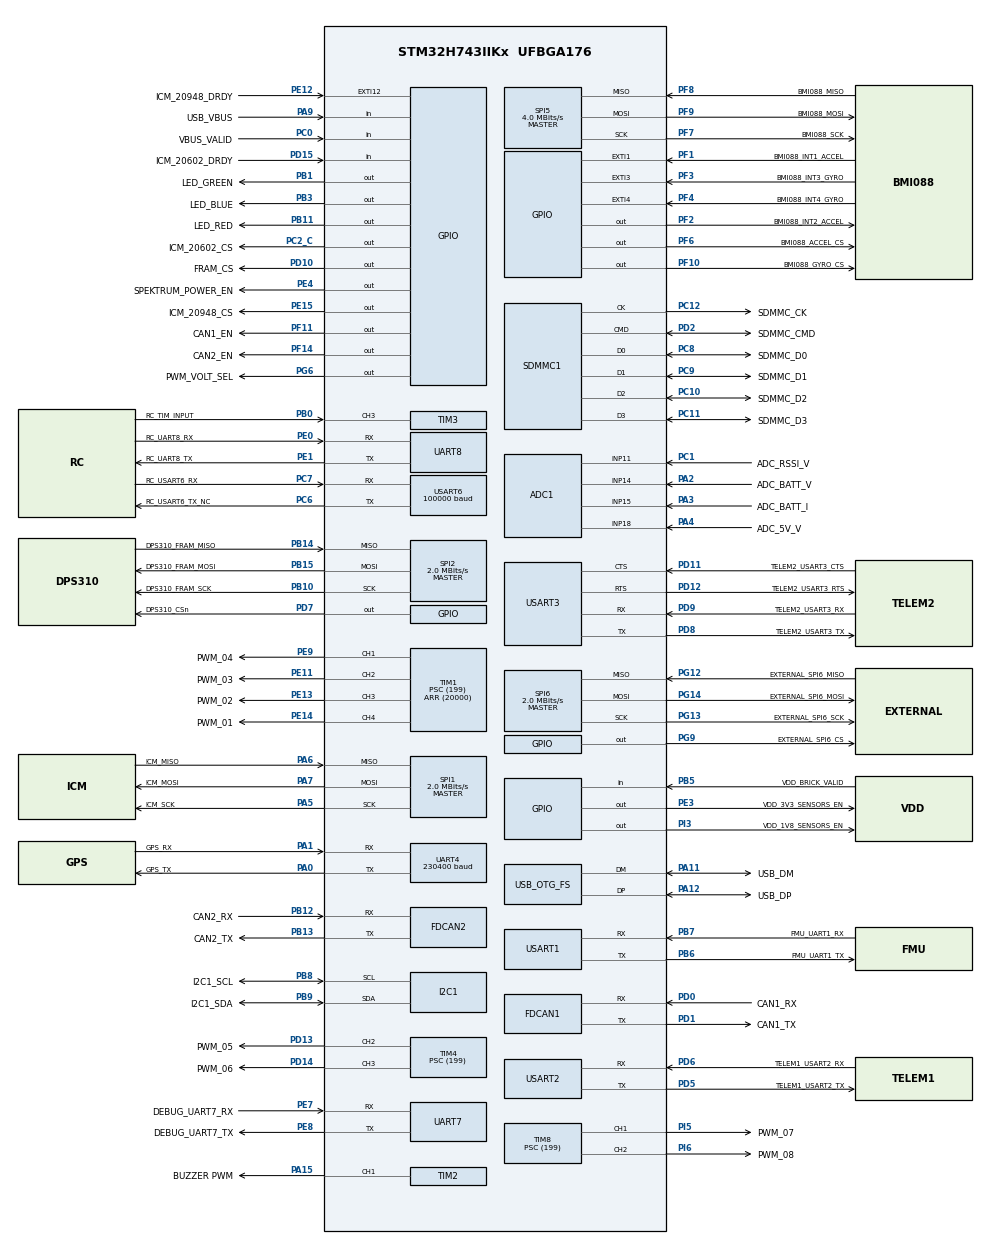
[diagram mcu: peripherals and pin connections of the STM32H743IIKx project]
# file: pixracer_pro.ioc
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ADC1.Channel-0\#ChannelRegularConversion=ADC_CHANNEL_11
ADC1.Channel-1\#ChannelRegularConversion=ADC_CHANNEL_14
ADC1.Channel-2\#ChannelRegularConversion=ADC_CHANNEL_15
ADC1.Channel-3\#ChannelRegularConversion=ADC_CHANNEL_18
ADC1.ClockPrescaler=ADC_CLOCK_ASYNC_DIV32
ADC1.ClockPrescalerADC3=ADC_CLOCK_ASYNC_DIV32
ADC1.ContinuousConvMode=DISABLE
ADC1.ConversionDataManagement=ADC_CONVERSIONDATA_DMA_ONESHOT
ADC1.EOCSelection=ADC_EOC_SEQ_CONV
ADC1.NbrOfConversion=4
ADC1.NbrOfConversionFlag=1
ADC1.OffsetNumber-0\#ChannelRegularConversion=ADC_OFFSET_NONE
ADC1.OffsetNumber-1\#ChannelRegularConversion=ADC_OFFSET_NONE
ADC1.OffsetNumber-2\#ChannelRegularConversion=ADC_OFFSET_NONE
ADC1.OffsetNumber-3\#ChannelRegularConversion=ADC_OFFSET_NONE
ADC1.OffsetSignedSaturation-0\#ChannelRegularConversion=DISABLE
ADC1.OffsetSignedSaturation-1\#ChannelRegularConversion=DISABLE
ADC1.OffsetSignedSaturation-2\#ChannelRegularConversion=DISABLE
ADC1.OffsetSignedSaturation-3\#ChannelRegularConversion=DISABLE
ADC1.Rank-0\#ChannelRegularConversion=1
ADC1.Rank-1\#ChannelRegularConversion=2
ADC1.Rank-2\#ChannelRegularConversion=3
ADC1.Rank-3\#ChannelRegularConversion=4
ADC1.SamplingTime-0\#ChannelRegularConversion=ADC_SAMPLETIME_810CYCLES_5
ADC1.SamplingTime-1\#ChannelRegularConversion=ADC_SAMPLETIME_810CYCLES_5
ADC1.SamplingTime-2\#ChannelRegularConversion=ADC_SAMPLETIME_810CYCLES_5
ADC1.SamplingTime-3\#ChannelRegularConversion=ADC_SAMPLETIME_810CYCLES_5
ADC1.master=1
ADC3.Channel-0\#ChannelRegularConversion=ADC_CHANNEL_TEMPSENSOR
ADC3.Channel-1\#ChannelRegularConversion=ADC_CHANNEL_VBAT
ADC3.Channel-2\#ChannelRegularConversion=ADC_CHANNEL_VREFINT
ADC3.ClockPrescalerADC3=ADC_CLOCK_ASYNC_DIV32
ADC3.ConversionDataManagement=ADC_CONVERSIONDATA_DMA_ONESHOT
ADC3.EOCSelection=ADC_EOC_SEQ_CONV
ADC3.NbrOfConversion=3
ADC3.NbrOfConversionFlag=1
ADC3.OffsetNumber-0\#ChannelRegularConversion=ADC_OFFSET_NONE
ADC3.OffsetNumber-1\#ChannelRegularConversion=ADC_OFFSET_NONE
ADC3.OffsetNumber-2\#ChannelRegularConversion=ADC_OFFSET_NONE
ADC3.OffsetSignedSaturation-0\#ChannelRegularConversion=DISABLE
ADC3.OffsetSignedSaturation-1\#ChannelRegularConversion=DISABLE
ADC3.OffsetSignedSaturation-2\#ChannelRegularConversion=DISABLE
ADC3.Rank-0\#ChannelRegularConversion=1
ADC3.Rank-1\#ChannelRegularConversion=2
ADC3.Rank-2\#ChannelRegularConversion=3
ADC3.SamplingTime-0\#ChannelRegularConversion=ADC_SAMPLETIME_810CYCLES_5
ADC3.SamplingTime-1\#ChannelRegularConversion=ADC_SAMPLETIME_810CYCLES_5
ADC3.SamplingTime-2\#ChannelRegularConversion=ADC_SAMPLETIME_810CYCLES_5
Bdma.ADC3.0.Direction=DMA_PERIPH_TO_MEMORY
Bdma.ADC3.0.EventEnable=DISABLE
Bdma.ADC3.0.Instance=BDMA_Channel0
Bdma.ADC3.0.MemDataAlignment=DMA_MDATAALIGN_WORD
Bdma.ADC3.0.MemInc=DMA_MINC_ENABLE
Bdma.ADC3.0.Mode=DMA_NORMAL
Bdma.ADC3.0.PeriphDataAlignment=DMA_PDATAALIGN_WORD
Bdma.ADC3.0.PeriphInc=DMA_PINC_DISABLE
Bdma.ADC3.0.Polarity=HAL_DMAMUX_REQ_GEN_RISING
Bdma.ADC3.0.Priority=DMA_PRIORITY_LOW
Bdma.ADC3.0.RequestNumber=1
Bdma.ADC3.0.SignalID=NONE
Bdma.ADC3.0.SyncEnable=DISABLE
Bdma.ADC3.0.SyncPolarity=HAL_DMAMUX_SYNC_NO_EVENT
Bdma.ADC3.0.SyncRequestNumber=1
Bdma.ADC3.0.SyncSignalID=NONE
Bdma.Request0=ADC3
Bdma.Request1=SPI6_RX
Bdma.Request2=SPI6_TX
Bdma.RequestsNb=3
Bdma.SPI6_RX.1.Direction=DMA_PERIPH_TO_MEMORY
Bdma.SPI6_RX.1.EventEnable=DISABLE
Bdma.SPI6_RX.1.Instance=BDMA_Channel1
Bdma.SPI6_RX.1.MemDataAlignment=DMA_MDATAALIGN_BYTE
Bdma.SPI6_RX.1.MemInc=DMA_MINC_ENABLE
Bdma.SPI6_RX.1.Mode=DMA_NORMAL
Bdma.SPI6_RX.1.PeriphDataAlignment=DMA_PDATAALIGN_BYTE
Bdma.SPI6_RX.1.PeriphInc=DMA_PINC_DISABLE
Bdma.SPI6_RX.1.Polarity=HAL_DMAMUX_REQ_GEN_RISING
Bdma.SPI6_RX.1.Priority=DMA_PRIORITY_LOW
Bdma.SPI6_RX.1.RequestNumber=1
Bdma.SPI6_RX.1.SignalID=NONE
Bdma.SPI6_RX.1.SyncEnable=DISABLE
Bdma.SPI6_RX.1.SyncPolarity=HAL_DMAMUX_SYNC_NO_EVENT
Bdma.SPI6_RX.1.SyncRequestNumber=1
Bdma.SPI6_RX.1.SyncSignalID=NONE
Bdma.SPI6_TX.2.Direction=DMA_MEMORY_TO_PERIPH
Bdma.SPI6_TX.2.EventEnable=DISABLE
Bdma.SPI6_TX.2.Instance=BDMA_Channel2
Bdma.SPI6_TX.2.MemDataAlignment=DMA_MDATAALIGN_BYTE
Bdma.SPI6_TX.2.MemInc=DMA_MINC_ENABLE
Bdma.SPI6_TX.2.Mode=DMA_NORMAL
Bdma.SPI6_TX.2.PeriphDataAlignment=DMA_PDATAALIGN_BYTE
Bdma.SPI6_TX.2.PeriphInc=DMA_PINC_DISABLE
Bdma.SPI6_TX.2.Polarity=HAL_DMAMUX_REQ_GEN_RISING
Bdma.SPI6_TX.2.Priority=DMA_PRIORITY_LOW
Bdma.SPI6_TX.2.RequestNumber=1
Bdma.SPI6_TX.2.SignalID=NONE
Bdma.SPI6_TX.2.SyncEnable=DISABLE
Bdma.SPI6_TX.2.SyncPolarity=HAL_DMAMUX_SYNC_NO_EVENT
Bdma.SPI6_TX.2.SyncRequestNumber=1
Bdma.SPI6_TX.2.SyncSignalID=NONE
CORTEX_M7.AccessPermission-Cortex_Memory_Protection_Unit_Region0_Settings=MPU_REGION_FULL_ACCESS
CORTEX_M7.AccessPermission-Cortex_Memory_Protection_Unit_Region1_Settings=MPU_REGION_FULL_ACCESS
CORTEX_M7.BaseAddress-Cortex_Memory_Protection_Unit_Region0_Settings=0x30040000
CORTEX_M7.BaseAddress-Cortex_Memory_Protection_Unit_Region1_Settings=0x38000000
CORTEX_M7.CPU_DCache=Enabled
CORTEX_M7.CPU_ICache=Enabled
CORTEX_M7.Enable-Cortex_Memory_Protection_Unit_Region0_Settings=MPU_REGION_ENABLE
CORTEX_M7.Enable-Cortex_Memory_Protection_Unit_Region1_Settings=MPU_REGION_ENABLE
CORTEX_M7.IsCacheable-Cortex_Memory_Protection_Unit_Region0_Settings=MPU_ACCESS_CACHEABLE
CORTEX_M7.IsCacheable-Cortex_Memory_Protection_Unit_Region1_Settings=MPU_ACCESS_CACHEABLE
CORTEX_M7.IsShareable-Cortex_Memory_Protection_Unit_Region0_Settings=MPU_ACCESS_SHAREABLE
CORTEX_M7.IsShareable-Cortex_Memory_Protection_Unit_Region1_Settings=MPU_ACCESS_SHAREABLE
CORTEX_M7.MPU_Control=MPU_PRIVILEGED_DEFAULT
CORTEX_M7.Size-Cortex_Memory_Protection_Unit_Region0_Settings=MPU_REGION_SIZE_32KB
CORTEX_M7.Size-Cortex_Memory_Protection_Unit_Region1_Settings=MPU_REGION_SIZE_64KB
Dma.ADC1.0.Direction=DMA_PERIPH_TO_MEMORY
Dma.ADC1.0.EventEnable=DISABLE
Dma.ADC1.0.FIFOMode=DMA_FIFOMODE_ENABLE
Dma.ADC1.0.FIFOThreshold=DMA_FIFO_THRESHOLD_FULL
Dma.ADC1.0.Instance=DMA1_Stream0
Dma.ADC1.0.MemBurst=DMA_MBURST_SINGLE
Dma.ADC1.0.MemDataAlignment=DMA_MDATAALIGN_WORD
Dma.ADC1.0.MemInc=DMA_MINC_ENABLE
Dma.ADC1.0.Mode=DMA_NORMAL
Dma.ADC1.0.PeriphBurst=DMA_PBURST_SINGLE
Dma.ADC1.0.PeriphDataAlignment=DMA_PDATAALIGN_WORD
Dma.ADC1.0.PeriphInc=DMA_PINC_DISABLE
Dma.ADC1.0.Polarity=HAL_DMAMUX_REQ_GEN_RISING
Dma.ADC1.0.Priority=DMA_PRIORITY_LOW
Dma.ADC1.0.RequestNumber=1
Dma.ADC1.0.SignalID=NONE
Dma.ADC1.0.SyncEnable=DISABLE
Dma.ADC1.0.SyncPolarity=HAL_DMAMUX_SYNC_NO_EVENT
Dma.ADC1.0.SyncRequestNumber=1
Dma.ADC1.0.SyncSignalID=NONE
Dma.I2C1_RX.9.Direction=DMA_PERIPH_TO_MEMORY
Dma.I2C1_RX.9.EventEnable=DISABLE
Dma.I2C1_RX.9.FIFOMode=DMA_FIFOMODE_ENABLE
Dma.I2C1_RX.9.FIFOThreshold=DMA_FIFO_THRESHOLD_FULL
Dma.I2C1_RX.9.Instance=DMA2_Stream2
Dma.I2C1_RX.9.MemBurst=DMA_MBURST_SINGLE
Dma.I2C1_RX.9.MemDataAlignment=DMA_MDATAALIGN_BYTE
Dma.I2C1_RX.9.MemInc=DMA_MINC_ENABLE
Dma.I2C1_RX.9.Mode=DMA_NORMAL
Dma.I2C1_RX.9.PeriphBurst=DMA_PBURST_SINGLE
Dma.I2C1_RX.9.PeriphDataAlignment=DMA_PDATAALIGN_BYTE
Dma.I2C1_RX.9.PeriphInc=DMA_PINC_DISABLE
Dma.I2C1_RX.9.Polarity=HAL_DMAMUX_REQ_GEN_RISING
Dma.I2C1_RX.9.Priority=DMA_PRIORITY_LOW
Dma.I2C1_RX.9.RequestNumber=1
Dma.I2C1_RX.9.SignalID=NONE
Dma.I2C1_RX.9.SyncEnable=DISABLE
Dma.I2C1_RX.9.SyncPolarity=HAL_DMAMUX_SYNC_NO_EVENT
Dma.I2C1_RX.9.SyncRequestNumber=1
Dma.I2C1_RX.9.SyncSignalID=NONE
Dma.I2C1_TX.10.Direction=DMA_MEMORY_TO_PERIPH
Dma.I2C1_TX.10.EventEnable=DISABLE
Dma.I2C1_TX.10.FIFOMode=DMA_FIFOMODE_ENABLE
Dma.I2C1_TX.10.FIFOThreshold=DMA_FIFO_THRESHOLD_FULL
Dma.I2C1_TX.10.Instance=DMA2_Stream3
Dma.I2C1_TX.10.MemBurst=DMA_MBURST_SINGLE
Dma.I2C1_TX.10.MemDataAlignment=DMA_MDATAALIGN_BYTE
Dma.I2C1_TX.10.MemInc=DMA_MINC_ENABLE
Dma.I2C1_TX.10.Mode=DMA_NORMAL
Dma.I2C1_TX.10.PeriphBurst=DMA_PBURST_SINGLE
Dma.I2C1_TX.10.PeriphDataAlignment=DMA_PDATAALIGN_BYTE
Dma.I2C1_TX.10.PeriphInc=DMA_PINC_DISABLE
Dma.I2C1_TX.10.Polarity=HAL_DMAMUX_REQ_GEN_RISING
Dma.I2C1_TX.10.Priority=DMA_PRIORITY_LOW
Dma.I2C1_TX.10.RequestNumber=1
Dma.I2C1_TX.10.SignalID=NONE
Dma.I2C1_TX.10.SyncEnable=DISABLE
Dma.I2C1_TX.10.SyncPolarity=HAL_DMAMUX_SYNC_NO_EVENT
Dma.I2C1_TX.10.SyncRequestNumber=1
Dma.I2C1_TX.10.SyncSignalID=NONE
Dma.Request0=ADC1
Dma.Request1=SPI1_RX
Dma.Request10=I2C1_TX
Dma.Request11=TIM1_UP
Dma.Request12=USART2_TX
Dma.Request13=TIM8_UP
Dma.Request14=TIM4_UP
Dma.Request2=SPI1_TX
Dma.Request3=SPI2_RX
Dma.Request4=SPI2_TX
Dma.Request5=SPI5_RX
Dma.Request6=SPI5_TX
Dma.Request7=UART4_RX
Dma.Request8=USART6_RX
Dma.Request9=I2C1_RX
Dma.SPI1_RX.1.Direction=DMA_PERIPH_TO_MEMORY
Dma.SPI1_RX.1.EventEnable=DISABLE
Dma.SPI1_RX.1.FIFOMode=DMA_FIFOMODE_ENABLE
Dma.SPI1_RX.1.FIFOThreshold=DMA_FIFO_THRESHOLD_FULL
Dma.SPI1_RX.1.Instance=DMA1_Stream1
Dma.SPI1_RX.1.MemBurst=DMA_MBURST_SINGLE
Dma.SPI1_RX.1.MemDataAlignment=DMA_MDATAALIGN_BYTE
Dma.SPI1_RX.1.MemInc=DMA_MINC_ENABLE
Dma.SPI1_RX.1.Mode=DMA_NORMAL
Dma.SPI1_RX.1.PeriphBurst=DMA_PBURST_SINGLE
Dma.SPI1_RX.1.PeriphDataAlignment=DMA_PDATAALIGN_BYTE
Dma.SPI1_RX.1.PeriphInc=DMA_PINC_DISABLE
Dma.SPI1_RX.1.Polarity=HAL_DMAMUX_REQ_GEN_RISING
Dma.SPI1_RX.1.Priority=DMA_PRIORITY_LOW
Dma.SPI1_RX.1.RequestNumber=1
Dma.SPI1_RX.1.SignalID=NONE
Dma.SPI1_RX.1.SyncEnable=DISABLE
Dma.SPI1_RX.1.SyncPolarity=HAL_DMAMUX_SYNC_NO_EVENT
Dma.SPI1_RX.1.SyncRequestNumber=1
Dma.SPI1_RX.1.SyncSignalID=NONE
Dma.SPI1_TX.2.Direction=DMA_MEMORY_TO_PERIPH
Dma.SPI1_TX.2.EventEnable=DISABLE
Dma.SPI1_TX.2.FIFOMode=DMA_FIFOMODE_DISABLE
Dma.SPI1_TX.2.Instance=DMA1_Stream2
Dma.SPI1_TX.2.MemDataAlignment=DMA_MDATAALIGN_BYTE
Dma.SPI1_TX.2.MemInc=DMA_MINC_ENABLE
Dma.SPI1_TX.2.Mode=DMA_NORMAL
Dma.SPI1_TX.2.PeriphDataAlignment=DMA_PDATAALIGN_BYTE
Dma.SPI1_TX.2.PeriphInc=DMA_PINC_DISABLE
Dma.SPI1_TX.2.Polarity=HAL_DMAMUX_REQ_GEN_RISING
Dma.SPI1_TX.2.Priority=DMA_PRIORITY_LOW
Dma.SPI1_TX.2.RequestNumber=1
Dma.SPI1_TX.2.SignalID=NONE
Dma.SPI1_TX.2.SyncEnable=DISABLE
Dma.SPI1_TX.2.SyncPolarity=HAL_DMAMUX_SYNC_NO_EVENT
Dma.SPI1_TX.2.SyncRequestNumber=1
Dma.SPI1_TX.2.SyncSignalID=NONE
Dma.SPI2_RX.3.Direction=DMA_PERIPH_TO_MEMORY
Dma.SPI2_RX.3.EventEnable=DISABLE
Dma.SPI2_RX.3.FIFOMode=DMA_FIFOMODE_ENABLE
Dma.SPI2_RX.3.FIFOThreshold=DMA_FIFO_THRESHOLD_FULL
Dma.SPI2_RX.3.Instance=DMA1_Stream3
Dma.SPI2_RX.3.MemBurst=DMA_MBURST_SINGLE
Dma.SPI2_RX.3.MemDataAlignment=DMA_MDATAALIGN_BYTE
Dma.SPI2_RX.3.MemInc=DMA_MINC_ENABLE
Dma.SPI2_RX.3.Mode=DMA_NORMAL
Dma.SPI2_RX.3.PeriphBurst=DMA_PBURST_SINGLE
Dma.SPI2_RX.3.PeriphDataAlignment=DMA_PDATAALIGN_BYTE
Dma.SPI2_RX.3.PeriphInc=DMA_PINC_DISABLE
Dma.SPI2_RX.3.Polarity=HAL_DMAMUX_REQ_GEN_RISING
Dma.SPI2_RX.3.Priority=DMA_PRIORITY_LOW
Dma.SPI2_RX.3.RequestNumber=1
Dma.SPI2_RX.3.SignalID=NONE
Dma.SPI2_RX.3.SyncEnable=DISABLE
Dma.SPI2_RX.3.SyncPolarity=HAL_DMAMUX_SYNC_NO_EVENT
Dma.SPI2_RX.3.SyncRequestNumber=1
Dma.SPI2_RX.3.SyncSignalID=NONE
Dma.SPI2_TX.4.Direction=DMA_MEMORY_TO_PERIPH
Dma.SPI2_TX.4.EventEnable=DISABLE
Dma.SPI2_TX.4.FIFOMode=DMA_FIFOMODE_ENABLE
Dma.SPI2_TX.4.FIFOThreshold=DMA_FIFO_THRESHOLD_FULL
Dma.SPI2_TX.4.Instance=DMA1_Stream4
Dma.SPI2_TX.4.MemBurst=DMA_MBURST_SINGLE
Dma.SPI2_TX.4.MemDataAlignment=DMA_MDATAALIGN_BYTE
Dma.SPI2_TX.4.MemInc=DMA_MINC_ENABLE
Dma.SPI2_TX.4.Mode=DMA_NORMAL
Dma.SPI2_TX.4.PeriphBurst=DMA_PBURST_SINGLE
Dma.SPI2_TX.4.PeriphDataAlignment=DMA_PDATAALIGN_BYTE
Dma.SPI2_TX.4.PeriphInc=DMA_PINC_DISABLE
Dma.SPI2_TX.4.Polarity=HAL_DMAMUX_REQ_GEN_RISING
Dma.SPI2_TX.4.Priority=DMA_PRIORITY_LOW
Dma.SPI2_TX.4.RequestNumber=1
Dma.SPI2_TX.4.SignalID=NONE
Dma.SPI2_TX.4.SyncEnable=DISABLE
Dma.SPI2_TX.4.SyncPolarity=HAL_DMAMUX_SYNC_NO_EVENT
Dma.SPI2_TX.4.SyncRequestNumber=1
Dma.SPI2_TX.4.SyncSignalID=NONE
Dma.SPI5_RX.5.Direction=DMA_PERIPH_TO_MEMORY
Dma.SPI5_RX.5.EventEnable=DISABLE
Dma.SPI5_RX.5.FIFOMode=DMA_FIFOMODE_ENABLE
Dma.SPI5_RX.5.FIFOThreshold=DMA_FIFO_THRESHOLD_FULL
Dma.SPI5_RX.5.Instance=DMA1_Stream5
Dma.SPI5_RX.5.MemBurst=DMA_MBURST_SINGLE
Dma.SPI5_RX.5.MemDataAlignment=DMA_MDATAALIGN_BYTE
Dma.SPI5_RX.5.MemInc=DMA_MINC_ENABLE
Dma.SPI5_RX.5.Mode=DMA_NORMAL
Dma.SPI5_RX.5.PeriphBurst=DMA_PBURST_SINGLE
Dma.SPI5_RX.5.PeriphDataAlignment=DMA_PDATAALIGN_BYTE
Dma.SPI5_RX.5.PeriphInc=DMA_PINC_DISABLE
Dma.SPI5_RX.5.Polarity=HAL_DMAMUX_REQ_GEN_RISING
Dma.SPI5_RX.5.Priority=DMA_PRIORITY_LOW
Dma.SPI5_RX.5.RequestNumber=1
Dma.SPI5_RX.5.SignalID=NONE
Dma.SPI5_RX.5.SyncEnable=DISABLE
Dma.SPI5_RX.5.SyncPolarity=HAL_DMAMUX_SYNC_NO_EVENT
Dma.SPI5_RX.5.SyncRequestNumber=1
Dma.SPI5_RX.5.SyncSignalID=NONE
Dma.SPI5_TX.6.Direction=DMA_MEMORY_TO_PERIPH
Dma.SPI5_TX.6.EventEnable=DISABLE
Dma.SPI5_TX.6.FIFOMode=DMA_FIFOMODE_ENABLE
Dma.SPI5_TX.6.FIFOThreshold=DMA_FIFO_THRESHOLD_FULL
Dma.SPI5_TX.6.Instance=DMA1_Stream6
Dma.SPI5_TX.6.MemBurst=DMA_MBURST_SINGLE
Dma.SPI5_TX.6.MemDataAlignment=DMA_MDATAALIGN_BYTE
Dma.SPI5_TX.6.MemInc=DMA_MINC_ENABLE
Dma.SPI5_TX.6.Mode=DMA_NORMAL
Dma.SPI5_TX.6.PeriphBurst=DMA_PBURST_SINGLE
Dma.SPI5_TX.6.PeriphDataAlignment=DMA_PDATAALIGN_BYTE
Dma.SPI5_TX.6.PeriphInc=DMA_PINC_DISABLE
Dma.SPI5_TX.6.Polarity=HAL_DMAMUX_REQ_GEN_RISING
Dma.SPI5_TX.6.Priority=DMA_PRIORITY_LOW
Dma.SPI5_TX.6.RequestNumber=1
Dma.SPI5_TX.6.SignalID=NONE
Dma.SPI5_TX.6.SyncEnable=DISABLE
Dma.SPI5_TX.6.SyncPolarity=HAL_DMAMUX_SYNC_NO_EVENT
Dma.SPI5_TX.6.SyncRequestNumber=1
Dma.SPI5_TX.6.SyncSignalID=NONE
Dma.TIM1_UP.11.Direction=DMA_MEMORY_TO_PERIPH
Dma.TIM1_UP.11.EventEnable=DISABLE
Dma.TIM1_UP.11.FIFOMode=DMA_FIFOMODE_ENABLE
Dma.TIM1_UP.11.FIFOThreshold=DMA_FIFO_THRESHOLD_FULL
Dma.TIM1_UP.11.Instance=DMA2_Stream6
Dma.TIM1_UP.11.MemBurst=DMA_MBURST_SINGLE
Dma.TIM1_UP.11.MemDataAlignment=DMA_MDATAALIGN_WORD
Dma.TIM1_UP.11.MemInc=DMA_MINC_ENABLE
Dma.TIM1_UP.11.Mode=DMA_NORMAL
Dma.TIM1_UP.11.PeriphBurst=DMA_PBURST_SINGLE
Dma.TIM1_UP.11.PeriphDataAlignment=DMA_PDATAALIGN_WORD
Dma.TIM1_UP.11.PeriphInc=DMA_PINC_DISABLE
Dma.TIM1_UP.11.Polarity=HAL_DMAMUX_REQ_GEN_RISING
Dma.TIM1_UP.11.Priority=DMA_PRIORITY_LOW
Dma.TIM1_UP.11.RequestNumber=1
Dma.TIM1_UP.11.SignalID=NONE
Dma.TIM1_UP.11.SyncEnable=DISABLE
Dma.TIM1_UP.11.SyncPolarity=HAL_DMAMUX_SYNC_NO_EVENT
Dma.TIM1_UP.11.SyncRequestNumber=1
Dma.TIM1_UP.11.SyncSignalID=NONE
Dma.TIM4_UP.14.Direction=DMA_MEMORY_TO_PERIPH
Dma.TIM4_UP.14.EventEnable=DISABLE
Dma.TIM4_UP.14.FIFOMode=DMA_FIFOMODE_ENABLE
Dma.TIM4_UP.14.FIFOThreshold=DMA_FIFO_THRESHOLD_FULL
Dma.TIM4_UP.14.Instance=DMA2_Stream4
Dma.TIM4_UP.14.MemBurst=DMA_MBURST_SINGLE
Dma.TIM4_UP.14.MemDataAlignment=DMA_MDATAALIGN_WORD
Dma.TIM4_UP.14.MemInc=DMA_MINC_ENABLE
Dma.TIM4_UP.14.Mode=DMA_NORMAL
Dma.TIM4_UP.14.PeriphBurst=DMA_PBURST_SINGLE
Dma.TIM4_UP.14.PeriphDataAlignment=DMA_PDATAALIGN_WORD
Dma.TIM4_UP.14.PeriphInc=DMA_PINC_DISABLE
Dma.TIM4_UP.14.Polarity=HAL_DMAMUX_REQ_GEN_RISING
Dma.TIM4_UP.14.Priority=DMA_PRIORITY_LOW
Dma.TIM4_UP.14.RequestNumber=1
Dma.TIM4_UP.14.SignalID=NONE
Dma.TIM4_UP.14.SyncEnable=DISABLE
Dma.TIM4_UP.14.SyncPolarity=HAL_DMAMUX_SYNC_NO_EVENT
Dma.TIM4_UP.14.SyncRequestNumber=1
Dma.TIM4_UP.14.SyncSignalID=NONE
Dma.TIM8_UP.13.Direction=DMA_MEMORY_TO_PERIPH
Dma.TIM8_UP.13.EventEnable=DISABLE
Dma.TIM8_UP.13.FIFOMode=DMA_FIFOMODE_ENABLE
Dma.TIM8_UP.13.FIFOThreshold=DMA_FIFO_THRESHOLD_FULL
Dma.TIM8_UP.13.Instance=DMA2_Stream5
Dma.TIM8_UP.13.MemBurst=DMA_MBURST_SINGLE
Dma.TIM8_UP.13.MemDataAlignment=DMA_MDATAALIGN_WORD
Dma.TIM8_UP.13.MemInc=DMA_MINC_ENABLE
Dma.TIM8_UP.13.Mode=DMA_NORMAL
Dma.TIM8_UP.13.PeriphBurst=DMA_PBURST_SINGLE
Dma.TIM8_UP.13.PeriphDataAlignment=DMA_PDATAALIGN_WORD
Dma.TIM8_UP.13.PeriphInc=DMA_PINC_DISABLE
Dma.TIM8_UP.13.Polarity=HAL_DMAMUX_REQ_GEN_RISING
Dma.TIM8_UP.13.Priority=DMA_PRIORITY_LOW
Dma.TIM8_UP.13.RequestNumber=1
Dma.TIM8_UP.13.SignalID=NONE
Dma.TIM8_UP.13.SyncEnable=DISABLE
Dma.TIM8_UP.13.SyncPolarity=HAL_DMAMUX_SYNC_NO_EVENT
Dma.TIM8_UP.13.SyncRequestNumber=1
Dma.TIM8_UP.13.SyncSignalID=NONE
Dma.UART4_RX.7.Direction=DMA_PERIPH_TO_MEMORY
Dma.UART4_RX.7.EventEnable=DISABLE
Dma.UART4_RX.7.FIFOMode=DMA_FIFOMODE_ENABLE
Dma.UART4_RX.7.FIFOThreshold=DMA_FIFO_THRESHOLD_FULL
Dma.UART4_RX.7.Instance=DMA1_Stream7
Dma.UART4_RX.7.MemBurst=DMA_MBURST_SINGLE
Dma.UART4_RX.7.MemDataAlignment=DMA_MDATAALIGN_BYTE
Dma.UART4_RX.7.MemInc=DMA_MINC_ENABLE
Dma.UART4_RX.7.Mode=DMA_NORMAL
Dma.UART4_RX.7.PeriphBurst=DMA_PBURST_SINGLE
Dma.UART4_RX.7.PeriphDataAlignment=DMA_PDATAALIGN_BYTE
Dma.UART4_RX.7.PeriphInc=DMA_PINC_DISABLE
Dma.UART4_RX.7.Polarity=HAL_DMAMUX_REQ_GEN_RISING
Dma.UART4_RX.7.Priority=DMA_PRIORITY_LOW
Dma.UART4_RX.7.RequestNumber=1
Dma.UART4_RX.7.SignalID=NONE
Dma.UART4_RX.7.SyncEnable=DISABLE
Dma.UART4_RX.7.SyncPolarity=HAL_DMAMUX_SYNC_NO_EVENT
Dma.UART4_RX.7.SyncRequestNumber=1
Dma.UART4_RX.7.SyncSignalID=NONE
Dma.USART2_TX.12.Direction=DMA_MEMORY_TO_PERIPH
Dma.USART2_TX.12.EventEnable=DISABLE
Dma.USART2_TX.12.FIFOMode=DMA_FIFOMODE_ENABLE
Dma.USART2_TX.12.FIFOThreshold=DMA_FIFO_THRESHOLD_FULL
Dma.USART2_TX.12.Instance=DMA2_Stream0
Dma.USART2_TX.12.MemBurst=DMA_MBURST_SINGLE
Dma.USART2_TX.12.MemDataAlignment=DMA_MDATAALIGN_BYTE
Dma.USART2_TX.12.MemInc=DMA_MINC_ENABLE
Dma.USART2_TX.12.Mode=DMA_NORMAL
Dma.USART2_TX.12.PeriphBurst=DMA_PBURST_SINGLE
Dma.USART2_TX.12.PeriphDataAlignment=DMA_PDATAALIGN_BYTE
Dma.USART2_TX.12.PeriphInc=DMA_PINC_DISABLE
Dma.USART2_TX.12.Polarity=HAL_DMAMUX_REQ_GEN_RISING
Dma.USART2_TX.12.Priority=DMA_PRIORITY_LOW
Dma.USART2_TX.12.RequestNumber=1
Dma.USART2_TX.12.SignalID=NONE
Dma.USART2_TX.12.SyncEnable=DISABLE
Dma.USART2_TX.12.SyncPolarity=HAL_DMAMUX_SYNC_NO_EVENT
Dma.USART2_TX.12.SyncRequestNumber=1
Dma.USART2_TX.12.SyncSignalID=NONE
Dma.USART6_RX.8.Direction=DMA_PERIPH_TO_MEMORY
Dma.USART6_RX.8.EventEnable=DISABLE
Dma.USART6_RX.8.FIFOMode=DMA_FIFOMODE_ENABLE
Dma.USART6_RX.8.FIFOThreshold=DMA_FIFO_THRESHOLD_FULL
Dma.USART6_RX.8.Instance=DMA2_Stream1
Dma.USART6_RX.8.MemBurst=DMA_MBURST_SINGLE
Dma.USART6_RX.8.MemDataAlignment=DMA_MDATAALIGN_BYTE
Dma.USART6_RX.8.MemInc=DMA_MINC_ENABLE
Dma.USART6_RX.8.Mode=DMA_NORMAL
Dma.USART6_RX.8.PeriphBurst=DMA_PBURST_SINGLE
Dma.USART6_RX.8.PeriphDataAlignment=DMA_PDATAALIGN_BYTE
Dma.USART6_RX.8.PeriphInc=DMA_PINC_DISABLE
Dma.USART6_RX.8.Polarity=HAL_DMAMUX_REQ_GEN_RISING
Dma.USART6_RX.8.Priority=DMA_PRIORITY_LOW
Dma.USART6_RX.8.RequestNumber=1
Dma.USART6_RX.8.SignalID=NONE
Dma.USART6_RX.8.SyncEnable=DISABLE
Dma.USART6_RX.8.SyncPolarity=HAL_DMAMUX_SYNC_NO_EVENT
Dma.USART6_RX.8.SyncRequestNumber=1
Dma.USART6_RX.8.SyncSignalID=NONE
FDCAN1.CalculateBaudRateNominal=200000
FDCAN1.CalculateTimeBitNominal=5000
FDCAN1.CalculateTimeQuantumNominal=1000.0
FDCAN2.CalculateBaudRateNominal=200000
FDCAN2.CalculateTimeBitNominal=5000
FDCAN2.CalculateTimeQuantumNominal=1000.0
I2C1.Timing=0x10C0ECFF
Mcu.Family=STM32H7
Mcu.Name=STM32H743IIKx
Mcu.Package=UFBGA176
NVIC.ADC3_IRQn=true\:5\:0\:true\:false\:true\:true\:true\:true
NVIC.ADC_IRQn=true\:5\:0\:true\:false\:true\:true\:true\:true
NVIC.BDMA_Channel0_IRQn=true\:5\:0\:true\:false\:true\:false\:true\:true
NVIC.BDMA_Channel1_IRQn=true\:5\:0\:true\:false\:true\:false\:true\:true
NVIC.BDMA_Channel2_IRQn=true\:5\:0\:true\:false\:true\:false\:true\:true
NVIC.DMA1_Stream0_IRQn=true\:5\:0\:true\:false\:true\:false\:true\:true
NVIC.DMA1_Stream1_IRQn=true\:5\:0\:true\:false\:true\:false\:true\:true
NVIC.DMA1_Stream2_IRQn=true\:5\:0\:true\:false\:true\:false\:true\:true
NVIC.DMA1_Stream3_IRQn=true\:5\:0\:true\:false\:true\:false\:true\:true
NVIC.DMA1_Stream4_IRQn=true\:5\:0\:true\:false\:true\:false\:true\:true
NVIC.DMA1_Stream5_IRQn=true\:5\:0\:true\:false\:true\:false\:true\:true
NVIC.DMA1_Stream6_IRQn=true\:5\:0\:true\:false\:true\:false\:true\:true
NVIC.DMA1_Stream7_IRQn=true\:5\:0\:true\:false\:true\:false\:true\:true
NVIC.DMA2_Stream0_IRQn=true\:1\:0\:true\:false\:true\:false\:true\:true
NVIC.DMA2_Stream1_IRQn=true\:5\:0\:true\:false\:true\:false\:true\:true
NVIC.DMA2_Stream2_IRQn=true\:5\:0\:true\:false\:true\:false\:true\:true
NVIC.DMA2_Stream3_IRQn=true\:5\:0\:true\:false\:true\:false\:true\:true
NVIC.DMA2_Stream4_IRQn=true\:0\:0\:false\:false\:true\:false\:true\:true
NVIC.DMA2_Stream5_IRQn=true\:5\:0\:true\:false\:true\:false\:true\:true
NVIC.DMA2_Stream6_IRQn=true\:5\:0\:true\:false\:true\:false\:true\:true
NVIC.EXTI15_10_IRQn=true\:5\:0\:true\:false\:true\:true\:true\:true
NVIC.EXTI1_IRQn=true\:5\:0\:true\:false\:true\:true\:true\:true
NVIC.EXTI3_IRQn=true\:5\:0\:true\:false\:true\:true\:true\:true
NVIC.EXTI4_IRQn=true\:0\:0\:true\:false\:true\:true\:true\:true
NVIC.I2C1_EV_IRQn=true\:5\:0\:true\:false\:true\:true\:true\:true
NVIC.OTG_FS_IRQn=true\:0\:0\:false\:false\:true\:true\:true\:true
NVIC.PriorityGroup=NVIC_PRIORITYGROUP_4
NVIC.SDMMC1_IRQn=true\:1\:0\:true\:false\:true\:true\:true\:true
NVIC.SPI1_IRQn=true\:5\:0\:true\:false\:true\:false\:true\:true
NVIC.SPI2_IRQn=true\:5\:0\:true\:false\:true\:false\:true\:true
NVIC.SPI5_IRQn=true\:5\:0\:true\:false\:true\:true\:true\:true
NVIC.SPI6_IRQn=true\:5\:0\:true\:false\:true\:true\:true\:true
NVIC.TIM7_IRQn=true\:5\:0\:true\:false\:true\:true\:true\:true
NVIC.UART4_IRQn=true\:5\:0\:true\:false\:true\:true\:true\:true
NVIC.UART7_IRQn=true\:5\:0\:true\:false\:true\:true\:true\:true
NVIC.UART8_IRQn=true\:5\:0\:true\:false\:true\:true\:true\:true
NVIC.USART1_IRQn=true\:5\:0\:true\:false\:true\:true\:true\:true
NVIC.USART2_IRQn=true\:1\:0\:true\:false\:true\:true\:true\:true
NVIC.USART3_IRQn=true\:5\:0\:true\:false\:true\:true\:true\:true
NVIC.USART6_IRQn=true\:5\:0\:true\:false\:true\:true\:true\:true
PA0.GPIO_Label=GPS_TX
PA0.Mode=Asynchronous
PA0.PinAttribute=Free
PA0.Signal=UART4_TX
PA1.GPIO_Label=GPS_RX
PA1.GPIO_PuPd=GPIO_PULLUP
PA1.Mode=Asynchronous
PA1.PinAttribute=Free
PA1.Signal=UART4_RX
PA11.GPIO_Label=USB_DM
PA11.Mode=Device_Only
PA11.PinAttribute=Free
PA11.Signal=USB_OTG_FS_DM
PA12.GPIO_Label=USB_DP
PA12.Mode=Device_Only
PA12.PinAttribute=Free
PA12.Signal=USB_OTG_FS_DP
PA13\ (JTMS/SWDIO).GPIO_Label=DEBUG_SWDIO
PA13\ (JTMS/SWDIO).Mode=Serial_Wire
PA13\ (JTMS/SWDIO).PinAttribute=Free
PA13\ (JTMS/SWDIO).Signal=DEBUG_JTMS-SWDIO
PA14\ (JTCK/SWCLK).GPIO_Label=DEBUG_SWCLK
PA14\ (JTCK/SWCLK).Mode=Serial_Wire
PA14\ (JTCK/SWCLK).PinAttribute=Free
PA14\ (JTCK/SWCLK).Signal=DEBUG_JTCK-SWCLK
PA15\ (JTDI).GPIO_Label=BUZZER PWM
PA15\ (JTDI).Signal=S_TIM2_CH1_ETR
PA2.GPIO_Label=ADC_BATT_V
PA2.PinAttribute=Free
PA2.Signal=ADCx_INP14
PA3.GPIO_Label=ADC_BATT_I
PA3.PinAttribute=Free
PA3.Signal=ADCx_INP15
PA4.GPIO_Label=ADC_5V_V
PA4.PinAttribute=Free
PA4.Signal=ADCx_INP18
PA5.GPIO_Label=ICM_SCK
PA5.Mode=Full_Duplex_Master
PA5.PinAttribute=Free
PA5.Signal=SPI1_SCK
PA6.GPIO_Label=ICM_MISO
PA6.Mode=Full_Duplex_Master
PA6.PinAttribute=Free
PA6.Signal=SPI1_MISO
PA7.GPIO_Label=ICM_MOSI
PA7.Mode=Full_Duplex_Master
PA7.PinAttribute=Free
PA7.Signal=SPI1_MOSI
PA9.GPIO_Label=USB_VBUS
PA9.Signal=GPIO_Input
PB0.GPIO_Label=RC_TIM_INPUT
PB0.PinAttribute=Free
PB0.Signal=S_TIM3_CH3
PB1.GPIO_Label=LED_GREEN
PB1.PinAttribute=Free
PB1.Signal=GPIO_Output
PB10.GPIO_Label=DPS310_FRAM_SCK
PB10.Mode=Full_Duplex_Master
PB10.PinAttribute=Free
PB10.Signal=SPI2_SCK
PB11.GPIO_Label=LED_RED
PB11.PinAttribute=Free
PB11.Signal=GPIO_Output
PB12.GPIO_Label=CAN2_RX
PB12.Mode=FDCAN_Activate
PB12.PinAttribute=Free
PB12.Signal=FDCAN2_RX
PB13.GPIO_Label=CAN2_TX
PB13.Mode=FDCAN_Activate
PB13.PinAttribute=Free
PB13.Signal=FDCAN2_TX
PB14.GPIO_Label=DPS310_FRAM_MISO
PB14.Mode=Full_Duplex_Master
PB14.PinAttribute=Free
PB14.Signal=SPI2_MISO
PB15.GPIO_Label=DPS310_FRAM_MOSI
PB15.Mode=Full_Duplex_Master
PB15.PinAttribute=Free
PB15.Signal=SPI2_MOSI
PB3\ (JTDO/TRACESWO).GPIO_Label=LED_BLUE
PB3\ (JTDO/TRACESWO).PinAttribute=Free
PB3\ (JTDO/TRACESWO).Signal=GPIO_Output
PB5.GPIO_Label=VDD_BRICK_VALID
PB5.PinAttribute=Free
PB5.Signal=GPIO_Input
PB6.GPIO_Label=FMU_UART1_TX
PB6.Mode=Asynchronous
PB6.PinAttribute=Free
PB6.Signal=USART1_TX
PB7.GPIO_Label=FMU_UART1_RX
PB7.GPIO_PuPd=GPIO_PULLUP
PB7.Mode=Asynchronous
PB7.PinAttribute=Free
PB7.Signal=USART1_RX
PB8.GPIO_Label=I2C1_SCL
PB8.Mode=I2C
PB8.PinAttribute=Free
PB8.Signal=I2C1_SCL
PB9.GPIO_Label=I2C1_SDA
PB9.Mode=I2C
PB9.PinAttribute=Free
PB9.Signal=I2C1_SDA
PC0.GPIO_Label=VBUS_VALID
PC0.PinAttribute=Free
PC0.Signal=GPIO_Input
PC1.GPIO_Label=ADC_RSSI_V
PC1.PinAttribute=Free
PC1.Signal=ADCx_INP11
PC10.GPIO_Label=SDMMC_D2
PC10.GPIO_PuPd=GPIO_PULLUP
PC10.Mode=SD_4_bits_Wide_bus
PC10.PinAttribute=Free
PC10.Signal=SDMMC1_D2
PC11.GPIO_Label=SDMMC_D3
PC11.GPIO_PuPd=GPIO_PULLUP
PC11.Mode=SD_4_bits_Wide_bus
PC11.PinAttribute=Free
PC11.Signal=SDMMC1_D3
PC12.GPIO_Label=SDMMC_CK
PC12.GPIO_PuPd=GPIO_PULLUP
PC12.Mode=SD_4_bits_Wide_bus
PC12.Signal=SDMMC1_CK
PC2_C.GPIO_Label=ICM_20602_CS
PC2_C.GPIO_PuPd=GPIO_PULLUP
PC2_C.PinAttribute=Free
PC2_C.PinState=GPIO_PIN_SET
PC2_C.Signal=GPIO_Output
PC6.GPIO_Label=RC_USART6_TX_NC
PC6.Mode=Asynchronous
PC6.PinAttribute=Free
PC6.Signal=USART6_TX
PC7.GPIO_Label=RC_USART6_RX 
PC7.GPIO_PuPd=GPIO_PULLUP
PC7.Mode=Asynchronous
PC7.PinAttribute=Free
PC7.Signal=USART6_RX
PC8.GPIO_Label=SDMMC_D0
PC8.GPIO_PuPd=GPIO_PULLUP
PC8.Mode=SD_4_bits_Wide_bus
PC8.PinAttribute=Free
PC8.Signal=SDMMC1_D0
PC9.GPIO_Label=SDMMC_D1
PC9.GPIO_PuPd=GPIO_PULLUP
PC9.Mode=SD_4_bits_Wide_bus
PC9.PinAttribute=Free
PC9.Signal=SDMMC1_D1
PD0.GPIO_Label=CAN1_RX
PD0.Mode=FDCAN_Activate
PD0.PinAttribute=Free
PD0.Signal=FDCAN1_RX
PD1.GPIO_Label=CAN1_TX
PD1.Mode=FDCAN_Activate
PD1.PinAttribute=Free
PD1.Signal=FDCAN1_TX
PD10.GPIO_Label=FRAM_CS
PD10.GPIO_PuPd=GPIO_PULLUP
PD10.PinAttribute=Free
PD10.PinState=GPIO_PIN_SET
PD10.Signal=GPIO_Output
PD11.GPIO_Label=TELEM2_USART3_CTS
PD11.Mode=CTS_RTS
PD11.PinAttribute=Free
PD11.Signal=USART3_CTS
PD12.GPIO_Label=TELEM2_USART3_RTS 
PD12.Mode=CTS_RTS
PD12.PinAttribute=Free
PD12.Signal=USART3_RTS
PD13.GPIO_Label=PWM_05
PD13.PinAttribute=Free
PD13.Signal=S_TIM4_CH2
PD14.GPIO_Label=PWM_06
PD14.PinAttribute=Free
PD14.Signal=S_TIM4_CH3
PD15.GPIO_Label=ICM_20602_DRDY
PD15.PinAttribute=Free
PD15.Signal=GPIO_Input
PD2.GPIO_Label=SDMMC_CMD
PD2.GPIO_PuPd=GPIO_PULLUP
PD2.Mode=SD_4_bits_Wide_bus
PD2.PinAttribute=Free
PD2.Signal=SDMMC1_CMD
PD3.GPIO_Label=TELEM1_USART2_CTS 
PD3.PinAttribute=Free
PD3.Signal=USART2_CTS
PD4.GPIO_Label=TELEM1_USART2_RTS 
PD4.PinAttribute=Free
PD4.Signal=USART2_RTS
PD5.GPIO_Label=TELEM1_USART2_TX
PD5.Mode=Asynchronous
PD5.PinAttribute=Free
PD5.Signal=USART2_TX
PD6.GPIO_Label=TELEM1_USART2_RX
PD6.GPIO_PuPd=GPIO_PULLUP
PD6.Mode=Asynchronous
PD6.PinAttribute=Free
PD6.Signal=USART2_RX
PD7.GPIO_Label=DPS310_CSn
PD7.GPIO_PuPd=GPIO_PULLUP
PD7.PinAttribute=Free
PD7.PinState=GPIO_PIN_SET
PD7.Signal=GPIO_Output
PD8.GPIO_Label=TELEM2_USART3_TX 
PD8.GPIO_PuPd=GPIO_NOPULL
PD8.Mode=Asynchronous
PD8.PinAttribute=Free
PD8.Signal=USART3_TX
PD9.GPIO_Label=TELEM2_USART3_RX 
PD9.GPIO_PuPd=GPIO_PULLUP
PD9.Mode=Asynchronous
PD9.PinAttribute=Free
PD9.Signal=USART3_RX
PE0.GPIO_Label=RC_UART8_RX
PE0.Mode=Asynchronous
PE0.Signal=UART8_RX
PE1.GPIO_Label=RC_UART8_TX
PE1.Mode=Asynchronous
PE1.Signal=UART8_TX
PE11.GPIO_Label=PWM_03
PE11.PinAttribute=Free
PE11.Signal=S_TIM1_CH2
PE12.GPIO_Label=ICM_20948_DRDY
PE12.PinAttribute=Free
PE12.Signal=GPXTI12
PE13.GPIO_Label=PWM_02
PE13.PinAttribute=Free
PE13.Signal=S_TIM1_CH3
PE14.GPIO_Label=PWM_01
PE14.PinAttribute=Free
PE14.Signal=S_TIM1_CH4
PE15.GPIO_Label=ICM_20948_CS
PE15.GPIO_PuPd=GPIO_PULLUP
PE15.PinAttribute=Free
PE15.PinState=GPIO_PIN_SET
PE15.Signal=GPIO_Output
PE3.GPIO_Label=VDD_3V3_SENSORS_EN
PE3.GPIO_PuPd=GPIO_PULLUP
PE3.PinState=GPIO_PIN_SET
PE3.Signal=GPIO_Output
PE4.GPIO_Label=SPEKTRUM_POWER_EN
PE4.GPIO_PuPd=GPIO_PULLUP
PE4.PinAttribute=Free
PE4.PinState=GPIO_PIN_SET
PE4.Signal=GPIO_Output
PE7.GPIO_Label=DEBUG_UART7_RX
PE7.Mode=Asynchronous
PE7.Signal=UART7_RX
PE8.GPIO_Label=DEBUG_UART7_TX
PE8.Mode=Asynchronous
PE8.PinAttribute=Free
PE8.Signal=UART7_TX
PE9.GPIO_Label=PWM_04
PE9.PinAttribute=Free
PE9.Signal=S_TIM1_CH1
PF1.GPIO_Label=BMI088_INT1_ACCEL
PF1.PinAttribute=Free
PF1.Signal=GPXTI1
PF10.GPIO_Label=BMI088_GYRO_CS
PF10.GPIO_PuPd=GPIO_PULLUP
PF10.PinAttribute=Free
PF10.PinState=GPIO_PIN_SET
PF10.Signal=GPIO_Output
PF11.GPIO_Label=CAN1_EN
PF11.PinAttribute=Free
PF11.Signal=GPIO_Output
PF14.GPIO_Label=CAN2_EN
PF14.PinAttribute=Free
PF14.Signal=GPIO_Output
PF2.GPIO_Label=BMI088_INT2_ACCEL
PF2.Signal=GPIO_Output
PF3.GPIO_Label=BMI088_INT3_GYRO
PF3.PinAttribute=Free
PF3.Signal=GPXTI3
PF4.GPIO_Label=BMI088_INT4_GYRO
PF4.PinAttribute=Free
PF4.Signal=GPXTI4
PF6.GPIO_Label=BMI088_ACCEL_CS
PF6.GPIO_PuPd=GPIO_PULLUP
PF6.PinAttribute=Free
PF6.PinState=GPIO_PIN_SET
PF6.Signal=GPIO_Output
PF7.GPIO_Label=BMI088_SCK
PF7.Mode=Full_Duplex_Master
PF7.PinAttribute=Free
PF7.Signal=SPI5_SCK
PF8.GPIO_Label=BMI088_MISO
PF8.Mode=Full_Duplex_Master
PF8.PinAttribute=Free
PF8.Signal=SPI5_MISO
PF9.GPIO_Label=BMI088_MOSI
PF9.Mode=Full_Duplex_Master
PF9.PinAttribute=Free
PF9.Signal=SPI5_MOSI
PG12.GPIO_Label=EXTERNAL_SPI6_MISO
PG12.Mode=Full_Duplex_Master
PG12.PinAttribute=Free
PG12.Signal=SPI6_MISO
PG13.GPIO_Label=EXTERNAL_SPI6_SCK
PG13.Mode=Full_Duplex_Master
PG13.PinAttribute=Free
PG13.Signal=SPI6_SCK
PG14.GPIO_Label=EXTERNAL_SPI6_MOSI
PG14.Mode=Full_Duplex_Master
PG14.PinAttribute=Free
PG14.Signal=SPI6_MOSI
PG6.GPIO_Label=PWM_VOLT_SEL
PG6.PinAttribute=Free
PG6.PinState=GPIO_PIN_SET
PG6.Signal=GPIO_Output
PG9.GPIO_Label=EXTERNAL_SPI6_CS
PG9.GPIO_PuPd=GPIO_PULLUP
PG9.PinAttribute=Free
PG9.PinState=GPIO_PIN_SET
PG9.Signal=GPIO_Output
PH0-OSC_IN\ (PH0).GPIO_Label=CRYSTAL_24MHz_IN
PH0-OSC_IN\ (PH0).Mode=HSE-External-Oscillator
PH0-OSC_IN\ (PH0).PinAttribute=Free
PH0-OSC_IN\ (PH0).Signal=RCC_OSC_IN
PH1-OSC_OUT\ (PH1).GPIO_Label=CRYSTAL_24MHz_OUT
PH1-OSC_OUT\ (PH1).Mode=HSE-External-Oscillator
PH1-OSC_OUT\ (PH1).PinAttribute=Free
PH1-OSC_OUT\ (PH1).Signal=RCC_OSC_OUT
PI3.GPIO_Label=VDD_1V8_SENSORS_EN
PI3.PinAttribute=Free
PI3.PinState=GPIO_PIN_SET
PI3.Signal=GPIO_Output
PI5.GPIO_Label=PWM_07
PI5.PinAttribute=Free
PI5.Signal=S_TIM8_CH1
PI6.GPIO_Label=PWM_08
PI6.PinAttribute=Free
PI6.Signal=S_TIM8_CH2
ProjectManager.HeapSize=0x4000
ProjectManager.StackSize=0x4000
ProjectManager.TargetToolchain=STM32CubeIDE
RCC.ADCCLockSelection=RCC_ADCCLKSOURCE_PLL3
RCC.ADCFreq_Value=64000000
RCC.APB1Freq_Value=100000000
RCC.APB2Freq_Value=100000000
RCC.APB3Freq_Value=100000000
RCC.APB4Freq_Value=100000000
RCC.CortexFreq_Value=400000000
RCC.D1PPRE=RCC_APB3_DIV2
RCC.D2PPRE1=RCC_APB1_DIV2
RCC.D2PPRE2=RCC_APB2_DIV2
RCC.D3PPRE=RCC_APB4_DIV2
RCC.DIVM1=12
RCC.DIVM2=12
RCC.DIVM3=12
RCC.DIVN1=400
RCC.DIVN2=240
RCC.DIVN3=480
RCC.DIVP2=30
RCC.DIVP3=60
RCC.DIVQ1=8
RCC.DIVQ2=30
RCC.DIVQ3=20
RCC.DIVR3=15
RCC.FDCANCLockSelection=RCC_FDCANCLKSOURCE_PLL2
RCC.FLatency-AdvancedSettings=FLASH_LATENCY_0
RCC.HCLKFreq_Value=200000000
RCC.HPRE=RCC_HCLK_DIV2
RCC.HSE_VALUE=24000000
RCC.PLL1_VCI_Range-AdvancedSettings=RCC_PLL1VCIRANGE_0
RCC.PLL2_VCI_Range-AdvancedSettings=RCC_PLL2VCIRANGE_0
RCC.PLL3FRACN=0
RCC.PLLSourceVirtual=RCC_PLLSOURCE_HSE
RCC.SPI123CLockSelection=RCC_SPI123CLKSOURCE_PLL2
RCC.SPI6CLockSelection=RCC_SPI6CLKSOURCE_PLL2
RCC.SYSCLKFreq_VALUE=400000000
RCC.SYSCLKSource=RCC_SYSCLKSOURCE_PLLCLK
RCC.Spi45ClockSelection=RCC_SPI45CLKSOURCE_PLL2
RCC.USBCLockSelection=RCC_USBCLKSOURCE_PLL3
RCC.USBFreq_Value=48000000
SDMMC1.ClockDiv=10
SH.ADCx_INP11.0=ADC1_INP11,IN11-Single-Ended
SH.ADCx_INP14.0=ADC1_INP14,IN14-Single-Ended
SH.ADCx_INP15.0=ADC1_INP15,IN15-Single-Ended
SH.ADCx_INP18.0=ADC1_INP18,IN18-Single-Ended
SH.S_TIM1_CH1.0=TIM1_CH1,PWM Generation1 CH1
SH.S_TIM1_CH2.0=TIM1_CH2,PWM Generation2 CH2
SH.S_TIM1_CH3.0=TIM1_CH3,PWM Generation3 CH3
SH.S_TIM1_CH4.0=TIM1_CH4,PWM Generation4 CH4
SH.S_TIM2_CH1_ETR.0=TIM2_CH1,PWM Generation1 CH1
SH.S_TIM3_CH3.0=TIM3_CH3,Input_Capture3_from_TI3
SH.S_TIM4_CH2.0=TIM4_CH2,PWM Generation2 CH2
SH.S_TIM4_CH3.0=TIM4_CH3,PWM Generation3 CH3
SH.S_TIM8_CH1.0=TIM8_CH1,PWM Generation1 CH1
SH.S_TIM8_CH2.0=TIM8_CH2,PWM Generation2 CH2
SPI1.BaudRatePrescaler=SPI_BAUDRATEPRESCALER_8
SPI1.CLKPhase=SPI_PHASE_2EDGE
SPI1.CLKPolarity=SPI_POLARITY_HIGH
SPI1.CalculateBaudRate=2.0 MBits/s
SPI1.DataSize=SPI_DATASIZE_8BIT
SPI1.Direction=SPI_DIRECTION_2LINES
SPI1.MasterKeepIOState=SPI_MASTER_KEEP_IO_STATE_ENABLE
SPI1.Mode=SPI_MODE_MASTER
SPI1.VirtualType=VM_MASTER
SPI2.BaudRatePrescaler=SPI_BAUDRATEPRESCALER_8
SPI2.CLKPhase=SPI_PHASE_2EDGE
SPI2.CLKPolarity=SPI_POLARITY_HIGH
SPI2.CalculateBaudRate=2.0 MBits/s
SPI2.DataSize=SPI_DATASIZE_8BIT
SPI2.Direction=SPI_DIRECTION_2LINES
SPI2.MasterKeepIOState=SPI_MASTER_KEEP_IO_STATE_ENABLE
SPI2.Mode=SPI_MODE_MASTER
SPI2.VirtualType=VM_MASTER
SPI5.BaudRatePrescaler=SPI_BAUDRATEPRESCALER_4
SPI5.CLKPhase=SPI_PHASE_2EDGE
SPI5.CLKPolarity=SPI_POLARITY_HIGH
SPI5.CalculateBaudRate=4.0 MBits/s
SPI5.DataSize=SPI_DATASIZE_8BIT
SPI5.Direction=SPI_DIRECTION_2LINES
SPI5.MasterKeepIOState=SPI_MASTER_KEEP_IO_STATE_ENABLE
SPI5.Mode=SPI_MODE_MASTER
SPI5.VirtualType=VM_MASTER
SPI6.BaudRatePrescaler=SPI_BAUDRATEPRESCALER_8
SPI6.CLKPhase=SPI_PHASE_2EDGE
SPI6.CLKPolarity=SPI_POLARITY_HIGH
SPI6.CalculateBaudRate=2.0 MBits/s
SPI6.DataSize=SPI_DATASIZE_8BIT
SPI6.Direction=SPI_DIRECTION_2LINES
SPI6.MasterKeepIOState=SPI_MASTER_KEEP_IO_STATE_ENABLE
SPI6.Mode=SPI_MODE_MASTER
SPI6.VirtualType=VM_MASTER
TIM1.AutoReloadPreload=TIM_AUTORELOAD_PRELOAD_ENABLE
TIM1.Channel-PWM\ Generation1\ CH1=TIM_CHANNEL_1
TIM1.Channel-PWM\ Generation2\ CH2=TIM_CHANNEL_2
TIM1.Channel-PWM\ Generation3\ CH3=TIM_CHANNEL_3
TIM1.Channel-PWM\ Generation4\ CH4=TIM_CHANNEL_4
TIM1.Period=(20000)
TIM1.Prescaler=(199)
TIM1.Pulse-PWM\ Generation1\ CH1=(1500)
TIM1.Pulse-PWM\ Generation2\ CH2=(1500)
TIM1.Pulse-PWM\ Generation3\ CH3=(1500)
TIM1.Pulse-PWM\ Generation4\ CH4=(1500)
TIM12.TIM_MasterSlaveMode=TIM_MASTERSLAVEMODE_ENABLE
TIM2.Channel-PWM\ Generation1\ CH1=TIM_CHANNEL_1
TIM3.Channel-Input_Capture3_from_TI3=TIM_CHANNEL_3
TIM4.AutoReloadPreload=TIM_AUTORELOAD_PRELOAD_ENABLE
TIM4.Channel-PWM\ Generation2\ CH2=TIM_CHANNEL_2
TIM4.Channel-PWM\ Generation3\ CH3=TIM_CHANNEL_3
TIM4.Period=(20000)
TIM4.Prescaler=(199)
TIM4.Pulse-PWM\ Generation2\ CH2=(1500)
TIM4.Pulse-PWM\ Generation3\ CH3=(1500)
TIM5.Prescaler=199
TIM5.TIM_MasterOutputTrigger=TIM_TRGO_ENABLE
TIM7.AutoReloadPreload=TIM_AUTORELOAD_PRELOAD_ENABLE
TIM7.Period=(POLLING_PERIOD_US)
TIM7.Prescaler=199
TIM8.AutoReloadPreload=TIM_AUTORELOAD_PRELOAD_ENABLE
TIM8.Channel-PWM\ Generation1\ CH1=TIM_CHANNEL_1
TIM8.Channel-PWM\ Generation2\ CH2=TIM_CHANNEL_2
TIM8.Period=(20000)
TIM8.Prescaler=(199)
TIM8.Pulse-PWM\ Generation1\ CH1=(1500)
TIM8.Pulse-PWM\ Generation2\ CH2=(1500)
UART4.AutoBaudRateEnableParam=UART_ADVFEATURE_AUTOBAUDRATE_DISABLE
UART4.BaudRate=230400
UART4.FIFOMode=FIFOMODE_ENABLE
UART4.OverrunDisableParam=UART_ADVFEATURE_OVERRUN_DISABLE
UART4.RXFIFOThreshold=RXFIFO_THRESHOLD_FULL
UART4.TXFIFOThreshold=TXFIFO_THRESHOLD_EMPTY
USART1.VirtualMode-Asynchronous=VM_ASYNC
USART2.BaudRate=(UART2_BAUD)
USART2.VirtualMode-Asynchronous=VM_ASYNC
USART3.VirtualMode-Asynchronous=VM_ASYNC
USART6.BaudRate=100000
USART6.Parity=PARITY_EVEN
USART6.RxPinLevelInvertParam=ADVFEATURE_RXINV_ENABLE
USART6.StopBits=STOPBITS_2
USART6.TxPinLevelInvertParam=ADVFEATURE_TXINV_ENABLE
USART6.VirtualMode-Asynchronous=VM_ASYNC
USART6.WordLength=WORDLENGTH_9B
USB_OTG_FS.VirtualMode=Device_Only
USB_OTG_FS.battery_charging_enable=DISABLE
VP_ADC3_TempSens_Input.Mode=IN-TempSens
VP_ADC3_Vbat_Input.Mode=IN-Vbat
VP_ADC3_Vref_Input.Mode=IN-Vrefint
VP_CRC_VS_CRC.Mode=CRC_Activate
VP_RNG_VS_RNG.Mode=RNG_Activate
VP_RTC_VS_RTC_Activate.Mode=RTC_Enabled
VP_TIM12_VS_ClockSourceITR.Mode=TriggerSource_ITR1
VP_TIM12_VS_ControllerModeClock.Mode=Clock Mode
VP_TIM5_VS_ClockSourceINT.Mode=Internal
VP_TIM7_VS_ClockSourceINT.Mode=Enable_Timer
board=custom

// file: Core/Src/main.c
/* USER CODE BEGIN Header */
/**
  ******************************************************************************
  * @file           : main.c
  * @brief          : Main program body
  ******************************************************************************
  * @attention
  *
  * Copyright (c) 2024 STMicroelectronics.
  * All rights reserved.
  *
  * This software is licensed under terms that can be found in the LICENSE file
  * in the root directory of this software component.
  * If no LICENSE file comes with this software, it is provided AS-IS.
  *
  ******************************************************************************
  */
/* USER CODE END Header */
#include "main.h"

ADC_HandleTypeDef hadc1;
ADC_HandleTypeDef hadc3;
DMA_HandleTypeDef hdma_adc1;
DMA_HandleTypeDef hdma_adc3;

CRC_HandleTypeDef hcrc;

FDCAN_HandleTypeDef hfdcan1;
FDCAN_HandleTypeDef hfdcan2;

I2C_HandleTypeDef hi2c1;
DMA_HandleTypeDef hdma_i2c1_rx;
DMA_HandleTypeDef hdma_i2c1_tx;

RNG_HandleTypeDef hrng;

RTC_HandleTypeDef hrtc;

SD_HandleTypeDef hsd1;

SPI_HandleTypeDef hspi1;
SPI_HandleTypeDef hspi2;
SPI_HandleTypeDef hspi5;
SPI_HandleTypeDef hspi6;
DMA_HandleTypeDef hdma_spi1_rx;
DMA_HandleTypeDef hdma_spi1_tx;
DMA_HandleTypeDef hdma_spi2_rx;
DMA_HandleTypeDef hdma_spi2_tx;
DMA_HandleTypeDef hdma_spi5_rx;
DMA_HandleTypeDef hdma_spi5_tx;
DMA_HandleTypeDef hdma_spi6_rx;
DMA_HandleTypeDef hdma_spi6_tx;

TIM_HandleTypeDef htim1;
TIM_HandleTypeDef htim2;
TIM_HandleTypeDef htim3;
TIM_HandleTypeDef htim4;
TIM_HandleTypeDef htim5;
TIM_HandleTypeDef htim7;
TIM_HandleTypeDef htim8;
TIM_HandleTypeDef htim12;
DMA_HandleTypeDef hdma_tim1_up;
DMA_HandleTypeDef hdma_tim4_up;
DMA_HandleTypeDef hdma_tim8_up;

UART_HandleTypeDef huart4;
UART_HandleTypeDef huart7;
UART_HandleTypeDef huart8;
UART_HandleTypeDef huart1;
UART_HandleTypeDef huart2;
UART_HandleTypeDef huart3;
UART_HandleTypeDef huart6;
DMA_HandleTypeDef hdma_uart4_rx;
DMA_HandleTypeDef hdma_usart2_tx;
DMA_HandleTypeDef hdma_usart6_rx;

PCD_HandleTypeDef hpcd_USB_OTG_FS;

/* USER CODE BEGIN PV */

#include <BoardConfig.h>
#if 0
/* USER CODE END PV */

void SystemClock_Config(void);
void PeriphCommonClock_Config(void);
static void MPU_Config(void);

int main(void)
{

  /* MPU Configuration--------------------------------------------------------*/
  MPU_Config();
/* Enable the CPU Cache */

  /* Enable I-Cache---------------------------------------------------------*/
  SCB_EnableICache();

  /* Enable D-Cache---------------------------------------------------------*/
  SCB_EnableDCache();

  /* MCU Configuration--------------------------------------------------------*/

  /* Reset of all peripherals, Initializes the Flash interface and the Systick. */
  HAL_Init();

  /* Configure the system clock */
  SystemClock_Config();

/* Configure the peripherals common clocks */
  PeriphCommonClock_Config();

  /* Initialize all configured peripherals */
  MX_GPIO_Init();
  MX_DMA_Init();
  MX_BDMA_Init();
  MX_FDCAN2_Init();
  MX_I2C1_Init();
  MX_SDMMC1_SD_Init();
  MX_SPI1_Init();
  MX_SPI2_Init();
  MX_SPI5_Init();
  MX_SPI6_Init();
  MX_TIM1_Init();
  MX_TIM2_Init();
  MX_TIM4_Init();
  MX_TIM8_Init();
  MX_UART4_Init();
  MX_UART7_Init();
  MX_UART8_Init();
  MX_USART1_UART_Init();
  MX_USART2_UART_Init();
  MX_USART3_UART_Init();
  MX_USART6_UART_Init();
  MX_RNG_Init();
  MX_RTC_Init();
  MX_TIM5_Init();
  MX_TIM7_Init();
  MX_FDCAN1_Init();
  MX_ADC3_Init();
  MX_ADC1_Init();
  MX_CRC_Init();
  MX_USB_OTG_FS_PCD_Init();
  MX_TIM12_Init();
  MX_TIM3_Init();

  /* Infinite loop */
  while (1)
  {

    /* USER CODE BEGIN 3 */
  }
#endif
  void dummy(void) {
  /* USER CODE END 3 */
}

void SystemClock_Config(void)
{
  RCC_OscInitTypeDef RCC_OscInitStruct = {0};
  RCC_ClkInitTypeDef RCC_ClkInitStruct = {0};

  /** Supply configuration update enable
  */
  HAL_PWREx_ConfigSupply(PWR_LDO_SUPPLY);

  /** Configure the main internal regulator output voltage
  */
  __HAL_PWR_VOLTAGESCALING_CONFIG(PWR_REGULATOR_VOLTAGE_SCALE1);

  while(!__HAL_PWR_GET_FLAG(PWR_FLAG_VOSRDY)) {}

  /** Initializes the RCC Oscillators according to the specified parameters
  * in the RCC_OscInitTypeDef structure.
  */
  RCC_OscInitStruct.OscillatorType = RCC_OSCILLATORTYPE_HSI48|RCC_OSCILLATORTYPE_LSI
                              |RCC_OSCILLATORTYPE_HSE;
  RCC_OscInitStruct.HSEState = RCC_HSE_ON;
  RCC_OscInitStruct.LSIState = RCC_LSI_ON;
  RCC_OscInitStruct.HSI48State = RCC_HSI48_ON;
  RCC_OscInitStruct.PLL.PLLState = RCC_PLL_ON;
  RCC_OscInitStruct.PLL.PLLSource = RCC_PLLSOURCE_HSE;
  RCC_OscInitStruct.PLL.PLLM = 12;
  RCC_OscInitStruct.PLL.PLLN = 400;
  RCC_OscInitStruct.PLL.PLLP = 2;
  RCC_OscInitStruct.PLL.PLLQ = 8;
  RCC_OscInitStruct.PLL.PLLR = 2;
  RCC_OscInitStruct.PLL.PLLRGE = RCC_PLL1VCIRANGE_1;
  RCC_OscInitStruct.PLL.PLLVCOSEL = RCC_PLL1VCOWIDE;
  RCC_OscInitStruct.PLL.PLLFRACN = 0;
  if (HAL_RCC_OscConfig(&RCC_OscInitStruct) != HAL_OK)
  {
    Error_Handler();
  }

  /** Initializes the CPU, AHB and APB buses clocks
  */
  RCC_ClkInitStruct.ClockType = RCC_CLOCKTYPE_HCLK|RCC_CLOCKTYPE_SYSCLK
                              |RCC_CLOCKTYPE_PCLK1|RCC_CLOCKTYPE_PCLK2
                              |RCC_CLOCKTYPE_D3PCLK1|RCC_CLOCKTYPE_D1PCLK1;
  RCC_ClkInitStruct.SYSCLKSource = RCC_SYSCLKSOURCE_PLLCLK;
  RCC_ClkInitStruct.SYSCLKDivider = RCC_SYSCLK_DIV1;
  RCC_ClkInitStruct.AHBCLKDivider = RCC_HCLK_DIV2;
  RCC_ClkInitStruct.APB3CLKDivider = RCC_APB3_DIV2;
  RCC_ClkInitStruct.APB1CLKDivider = RCC_APB1_DIV2;
  RCC_ClkInitStruct.APB2CLKDivider = RCC_APB2_DIV2;
  RCC_ClkInitStruct.APB4CLKDivider = RCC_APB4_DIV2;

  if (HAL_RCC_ClockConfig(&RCC_ClkInitStruct, FLASH_LATENCY_2) != HAL_OK)
  {
    Error_Handler();
  }
}

void PeriphCommonClock_Config(void)
{
  RCC_PeriphCLKInitTypeDef PeriphClkInitStruct = {0};

  /** Initializes the peripherals clock
  */
  PeriphClkInitStruct.PeriphClockSelection = RCC_PERIPHCLK_USB|RCC_PERIPHCLK_SPI6
                              |RCC_PERIPHCLK_ADC|RCC_PERIPHCLK_SPI2
                              |RCC_PERIPHCLK_SPI1|RCC_PERIPHCLK_SPI5
                              |RCC_PERIPHCLK_FDCAN;
  PeriphClkInitStruct.PLL2.PLL2M = 12;
  PeriphClkInitStruct.PLL2.PLL2N = 240;
  PeriphClkInitStruct.PLL2.PLL2P = 30;
  PeriphClkInitStruct.PLL2.PLL2Q = 30;
  PeriphClkInitStruct.PLL2.PLL2R = 2;
  PeriphClkInitStruct.PLL2.PLL2RGE = RCC_PLL2VCIRANGE_1;
  PeriphClkInitStruct.PLL2.PLL2VCOSEL = RCC_PLL2VCOWIDE;
  PeriphClkInitStruct.PLL2.PLL2FRACN = 0;
  PeriphClkInitStruct.PLL3.PLL3M = 12;
  PeriphClkInitStruct.PLL3.PLL3N = 480;
  PeriphClkInitStruct.PLL3.PLL3P = 60;
  PeriphClkInitStruct.PLL3.PLL3Q = 20;
  PeriphClkInitStruct.PLL3.PLL3R = 15;
  PeriphClkInitStruct.PLL3.PLL3RGE = RCC_PLL3VCIRANGE_1;
  PeriphClkInitStruct.PLL3.PLL3VCOSEL = RCC_PLL3VCOWIDE;
  PeriphClkInitStruct.PLL3.PLL3FRACN = 0;
  PeriphClkInitStruct.Spi123ClockSelection = RCC_SPI123CLKSOURCE_PLL2;
  PeriphClkInitStruct.Spi45ClockSelection = RCC_SPI45CLKSOURCE_PLL2;
  PeriphClkInitStruct.FdcanClockSelection = RCC_FDCANCLKSOURCE_PLL2;
  PeriphClkInitStruct.UsbClockSelection = RCC_USBCLKSOURCE_PLL3;
  PeriphClkInitStruct.AdcClockSelection = RCC_ADCCLKSOURCE_PLL3;
  PeriphClkInitStruct.Spi6ClockSelection = RCC_SPI6CLKSOURCE_PLL2;
  if (HAL_RCCEx_PeriphCLKConfig(&PeriphClkInitStruct) != HAL_OK)
  {
    Error_Handler();
  }
}

void MX_ADC1_Init(void)
{

  ADC_MultiModeTypeDef multimode = {0};
  ADC_ChannelConfTypeDef sConfig = {0};

  /** Common config
  */
  hadc1.Instance = ADC1;
  hadc1.Init.ClockPrescaler = ADC_CLOCK_ASYNC_DIV32;
  hadc1.Init.Resolution = ADC_RESOLUTION_16B;
  hadc1.Init.ScanConvMode = ADC_SCAN_ENABLE;
  hadc1.Init.EOCSelection = ADC_EOC_SEQ_CONV;
  hadc1.Init.LowPowerAutoWait = DISABLE;
  hadc1.Init.ContinuousConvMode = DISABLE;
  hadc1.Init.NbrOfConversion = 4;
  hadc1.Init.DiscontinuousConvMode = DISABLE;
  hadc1.Init.ExternalTrigConv = ADC_SOFTWARE_START;
  hadc1.Init.ExternalTrigConvEdge = ADC_EXTERNALTRIGCONVEDGE_NONE;
  hadc1.Init.ConversionDataManagement = ADC_CONVERSIONDATA_DMA_ONESHOT;
  hadc1.Init.Overrun = ADC_OVR_DATA_PRESERVED;
  hadc1.Init.LeftBitShift = ADC_LEFTBITSHIFT_NONE;
  hadc1.Init.OversamplingMode = DISABLE;
  if (HAL_ADC_Init(&hadc1) != HAL_OK)
  {
    Error_Handler();
  }

  /** Configure the ADC multi-mode
  */
  multimode.Mode = ADC_MODE_INDEPENDENT;
  if (HAL_ADCEx_MultiModeConfigChannel(&hadc1, &multimode) != HAL_OK)
  {
    Error_Handler();
  }

  /** Configure Regular Channel
  */
  sConfig.Channel = ADC_CHANNEL_11;
  sConfig.Rank = ADC_REGULAR_RANK_1;
  sConfig.SamplingTime = ADC_SAMPLETIME_810CYCLES_5;
  sConfig.SingleDiff = ADC_SINGLE_ENDED;
  sConfig.OffsetNumber = ADC_OFFSET_NONE;
  sConfig.Offset = 0;
  sConfig.OffsetSignedSaturation = DISABLE;
  if (HAL_ADC_ConfigChannel(&hadc1, &sConfig) != HAL_OK)
  {
    Error_Handler();
  }

  /** Configure Regular Channel
  */
  sConfig.Channel = ADC_CHANNEL_14;
  sConfig.Rank = ADC_REGULAR_RANK_2;
  if (HAL_ADC_ConfigChannel(&hadc1, &sConfig) != HAL_OK)
  {
    Error_Handler();
  }

  /** Configure Regular Channel
  */
  sConfig.Channel = ADC_CHANNEL_15;
  sConfig.Rank = ADC_REGULAR_RANK_3;
  if (HAL_ADC_ConfigChannel(&hadc1, &sConfig) != HAL_OK)
  {
    Error_Handler();
  }

  /** Configure Regular Channel
  */
  sConfig.Channel = ADC_CHANNEL_18;
  sConfig.Rank = ADC_REGULAR_RANK_4;
  if (HAL_ADC_ConfigChannel(&hadc1, &sConfig) != HAL_OK)
  {
    Error_Handler();
  }

}

void MX_ADC3_Init(void)
{

  ADC_ChannelConfTypeDef sConfig = {0};

  /** Common config
  */
  hadc3.Instance = ADC3;
  hadc3.Init.Resolution = ADC_RESOLUTION_16B;
  hadc3.Init.ScanConvMode = ADC_SCAN_ENABLE;
  hadc3.Init.EOCSelection = ADC_EOC_SEQ_CONV;
  hadc3.Init.LowPowerAutoWait = DISABLE;
  hadc3.Init.ContinuousConvMode = DISABLE;
  hadc3.Init.NbrOfConversion = 3;
  hadc3.Init.DiscontinuousConvMode = DISABLE;
  hadc3.Init.ExternalTrigConv = ADC_SOFTWARE_START;
  hadc3.Init.ExternalTrigConvEdge = ADC_EXTERNALTRIGCONVEDGE_NONE;
  hadc3.Init.ConversionDataManagement = ADC_CONVERSIONDATA_DMA_ONESHOT;
  hadc3.Init.Overrun = ADC_OVR_DATA_PRESERVED;
  hadc3.Init.LeftBitShift = ADC_LEFTBITSHIFT_NONE;
  hadc3.Init.OversamplingMode = DISABLE;
  if (HAL_ADC_Init(&hadc3) != HAL_OK)
  {
    Error_Handler();
  }

  /** Configure Regular Channel
  */
  sConfig.Channel = ADC_CHANNEL_TEMPSENSOR;
  sConfig.Rank = ADC_REGULAR_RANK_1;
  sConfig.SamplingTime = ADC_SAMPLETIME_810CYCLES_5;
  sConfig.SingleDiff = ADC_SINGLE_ENDED;
  sConfig.OffsetNumber = ADC_OFFSET_NONE;
  sConfig.Offset = 0;
  sConfig.OffsetSignedSaturation = DISABLE;
  if (HAL_ADC_ConfigChannel(&hadc3, &sConfig) != HAL_OK)
  {
    Error_Handler();
  }

  /** Configure Regular Channel
  */
  sConfig.Channel = ADC_CHANNEL_VBAT;
  sConfig.Rank = ADC_REGULAR_RANK_2;
  if (HAL_ADC_ConfigChannel(&hadc3, &sConfig) != HAL_OK)
  {
    Error_Handler();
  }

  /** Configure Regular Channel
  */
  sConfig.Channel = ADC_CHANNEL_VREFINT;
  sConfig.Rank = ADC_REGULAR_RANK_3;
  if (HAL_ADC_ConfigChannel(&hadc3, &sConfig) != HAL_OK)
  {
    Error_Handler();
  }

}

void MX_CRC_Init(void)
{

  hcrc.Instance = CRC;
  hcrc.Init.DefaultPolynomialUse = DEFAULT_POLYNOMIAL_ENABLE;
  hcrc.Init.DefaultInitValueUse = DEFAULT_INIT_VALUE_ENABLE;
  hcrc.Init.InputDataInversionMode = CRC_INPUTDATA_INVERSION_NONE;
  hcrc.Init.OutputDataInversionMode = CRC_OUTPUTDATA_INVERSION_DISABLE;
  hcrc.InputDataFormat = CRC_INPUTDATA_FORMAT_BYTES;
  if (HAL_CRC_Init(&hcrc) != HAL_OK)
  {
    Error_Handler();
  }

}

void MX_FDCAN1_Init(void)
{

  hfdcan1.Instance = FDCAN1;
  hfdcan1.Init.FrameFormat = FDCAN_FRAME_CLASSIC;
  hfdcan1.Init.Mode = FDCAN_MODE_NORMAL;
  hfdcan1.Init.AutoRetransmission = DISABLE;
  hfdcan1.Init.TransmitPause = DISABLE;
  hfdcan1.Init.ProtocolException = DISABLE;
  hfdcan1.Init.NominalPrescaler = 16;
  hfdcan1.Init.NominalSyncJumpWidth = 1;
  hfdcan1.Init.NominalTimeSeg1 = 2;
  hfdcan1.Init.NominalTimeSeg2 = 2;
  hfdcan1.Init.DataPrescaler = 1;
  hfdcan1.Init.DataSyncJumpWidth = 1;
  hfdcan1.Init.DataTimeSeg1 = 1;
  hfdcan1.Init.DataTimeSeg2 = 1;
  hfdcan1.Init.MessageRAMOffset = 0;
  hfdcan1.Init.StdFiltersNbr = 0;
  hfdcan1.Init.ExtFiltersNbr = 0;
  hfdcan1.Init.RxFifo0ElmtsNbr = 0;
  hfdcan1.Init.RxFifo0ElmtSize = FDCAN_DATA_BYTES_8;
  hfdcan1.Init.RxFifo1ElmtsNbr = 0;
  hfdcan1.Init.RxFifo1ElmtSize = FDCAN_DATA_BYTES_8;
  hfdcan1.Init.RxBuffersNbr = 0;
  hfdcan1.Init.RxBufferSize = FDCAN_DATA_BYTES_8;
  hfdcan1.Init.TxEventsNbr = 0;
  hfdcan1.Init.TxBuffersNbr = 0;
  hfdcan1.Init.TxFifoQueueElmtsNbr = 0;
  hfdcan1.Init.TxFifoQueueMode = FDCAN_TX_FIFO_OPERATION;
  hfdcan1.Init.TxElmtSize = FDCAN_DATA_BYTES_8;
  if (HAL_FDCAN_Init(&hfdcan1) != HAL_OK)
  {
    Error_Handler();
  }

}

void MX_FDCAN2_Init(void)
{

  hfdcan2.Instance = FDCAN2;
  hfdcan2.Init.FrameFormat = FDCAN_FRAME_CLASSIC;
  hfdcan2.Init.Mode = FDCAN_MODE_NORMAL;
  hfdcan2.Init.AutoRetransmission = DISABLE;
  hfdcan2.Init.TransmitPause = DISABLE;
  hfdcan2.Init.ProtocolException = DISABLE;
  hfdcan2.Init.NominalPrescaler = 16;
  hfdcan2.Init.NominalSyncJumpWidth = 1;
  hfdcan2.Init.NominalTimeSeg1 = 2;
  hfdcan2.Init.NominalTimeSeg2 = 2;
  hfdcan2.Init.DataPrescaler = 1;
  hfdcan2.Init.DataSyncJumpWidth = 1;
  hfdcan2.Init.DataTimeSeg1 = 1;
  hfdcan2.Init.DataTimeSeg2 = 1;
  hfdcan2.Init.MessageRAMOffset = 0;
  hfdcan2.Init.StdFiltersNbr = 0;
  hfdcan2.Init.ExtFiltersNbr = 0;
  hfdcan2.Init.RxFifo0ElmtsNbr = 0;
  hfdcan2.Init.RxFifo0ElmtSize = FDCAN_DATA_BYTES_8;
  hfdcan2.Init.RxFifo1ElmtsNbr = 0;
  hfdcan2.Init.RxFifo1ElmtSize = FDCAN_DATA_BYTES_8;
  hfdcan2.Init.RxBuffersNbr = 0;
  hfdcan2.Init.RxBufferSize = FDCAN_DATA_BYTES_8;
  hfdcan2.Init.TxEventsNbr = 0;
  hfdcan2.Init.TxBuffersNbr = 0;
  hfdcan2.Init.TxFifoQueueElmtsNbr = 0;
  hfdcan2.Init.TxFifoQueueMode = FDCAN_TX_FIFO_OPERATION;
  hfdcan2.Init.TxElmtSize = FDCAN_DATA_BYTES_8;
  if (HAL_FDCAN_Init(&hfdcan2) != HAL_OK)
  {
    Error_Handler();
  }

}

void MX_I2C1_Init(void)
{

  hi2c1.Instance = I2C1;
  hi2c1.Init.Timing = 0x10C0ECFF;
  hi2c1.Init.OwnAddress1 = 0;
  hi2c1.Init.AddressingMode = I2C_ADDRESSINGMODE_7BIT;
  hi2c1.Init.DualAddressMode = I2C_DUALADDRESS_DISABLE;
  hi2c1.Init.OwnAddress2 = 0;
  hi2c1.Init.OwnAddress2Masks = I2C_OA2_NOMASK;
  hi2c1.Init.GeneralCallMode = I2C_GENERALCALL_DISABLE;
  hi2c1.Init.NoStretchMode = I2C_NOSTRETCH_DISABLE;
  if (HAL_I2C_Init(&hi2c1) != HAL_OK)
  {
    Error_Handler();
  }

  /** Configure Analogue filter
  */
  if (HAL_I2CEx_ConfigAnalogFilter(&hi2c1, I2C_ANALOGFILTER_ENABLE) != HAL_OK)
  {
    Error_Handler();
  }

  /** Configure Digital filter
  */
  if (HAL_I2CEx_ConfigDigitalFilter(&hi2c1, 0) != HAL_OK)
  {
    Error_Handler();
  }

}

void MX_RNG_Init(void)
{

  hrng.Instance = RNG;
  hrng.Init.ClockErrorDetection = RNG_CED_ENABLE;
  if (HAL_RNG_Init(&hrng) != HAL_OK)
  {
    Error_Handler();
  }

}

void MX_RTC_Init(void)
{

  /** Initialize RTC Only
  */
  hrtc.Instance = RTC;
  hrtc.Init.HourFormat = RTC_HOURFORMAT_24;
  hrtc.Init.AsynchPrediv = 127;
  hrtc.Init.SynchPrediv = 255;
  hrtc.Init.OutPut = RTC_OUTPUT_DISABLE;
  hrtc.Init.OutPutPolarity = RTC_OUTPUT_POLARITY_HIGH;
  hrtc.Init.OutPutType = RTC_OUTPUT_TYPE_OPENDRAIN;
  hrtc.Init.OutPutRemap = RTC_OUTPUT_REMAP_NONE;
  if (HAL_RTC_Init(&hrtc) != HAL_OK)
  {
    Error_Handler();
  }

}

void MX_SDMMC1_SD_Init(void)
{

  /* USER CODE BEGIN SDMMC1_Init 0 */
  hsd1.Instance = SDMMC1;
  hsd1.Init.ClockEdge = SDMMC_CLOCK_EDGE_RISING;
  hsd1.Init.ClockPowerSave = SDMMC_CLOCK_POWER_SAVE_DISABLE;
  hsd1.Init.BusWide = SDMMC_BUS_WIDE_4B;
  hsd1.Init.HardwareFlowControl = SDMMC_HARDWARE_FLOW_CONTROL_DISABLE;
  hsd1.Init.ClockDiv = 10;
  if (HAL_SD_Init(&hsd1) != HAL_OK)
  {

  }
  return;
  /* USER CODE END SDMMC1_Init 0 */

  hsd1.Instance = SDMMC1;
  hsd1.Init.ClockEdge = SDMMC_CLOCK_EDGE_RISING;
  hsd1.Init.ClockPowerSave = SDMMC_CLOCK_POWER_SAVE_DISABLE;
  hsd1.Init.BusWide = SDMMC_BUS_WIDE_4B;
  hsd1.Init.HardwareFlowControl = SDMMC_HARDWARE_FLOW_CONTROL_DISABLE;
  hsd1.Init.ClockDiv = 10;
  if (HAL_SD_Init(&hsd1) != HAL_OK)
  {
    Error_Handler();
  }

}

void MX_SPI1_Init(void)
{

  /* SPI1 parameter configuration*/
  hspi1.Instance = SPI1;
  hspi1.Init.Mode = SPI_MODE_MASTER;
  hspi1.Init.Direction = SPI_DIRECTION_2LINES;
  hspi1.Init.DataSize = SPI_DATASIZE_8BIT;
  hspi1.Init.CLKPolarity = SPI_POLARITY_HIGH;
  hspi1.Init.CLKPhase = SPI_PHASE_2EDGE;
  hspi1.Init.NSS = SPI_NSS_SOFT;
  hspi1.Init.BaudRatePrescaler = SPI_BAUDRATEPRESCALER_8;
  hspi1.Init.FirstBit = SPI_FIRSTBIT_MSB;
  hspi1.Init.TIMode = SPI_TIMODE_DISABLE;
  hspi1.Init.CRCCalculation = SPI_CRCCALCULATION_DISABLE;
  hspi1.Init.CRCPolynomial = 0x0;
  hspi1.Init.NSSPMode = SPI_NSS_PULSE_ENABLE;
  hspi1.Init.NSSPolarity = SPI_NSS_POLARITY_LOW;
  hspi1.Init.FifoThreshold = SPI_FIFO_THRESHOLD_01DATA;
  hspi1.Init.TxCRCInitializationPattern = SPI_CRC_INITIALIZATION_ALL_ZERO_PATTERN;
  hspi1.Init.RxCRCInitializationPattern = SPI_CRC_INITIALIZATION_ALL_ZERO_PATTERN;
  hspi1.Init.MasterSSIdleness = SPI_MASTER_SS_IDLENESS_00CYCLE;
  hspi1.Init.MasterInterDataIdleness = SPI_MASTER_INTERDATA_IDLENESS_00CYCLE;
  hspi1.Init.MasterReceiverAutoSusp = SPI_MASTER_RX_AUTOSUSP_DISABLE;
  hspi1.Init.MasterKeepIOState = SPI_MASTER_KEEP_IO_STATE_ENABLE;
  hspi1.Init.IOSwap = SPI_IO_SWAP_DISABLE;
  if (HAL_SPI_Init(&hspi1) != HAL_OK)
  {
    Error_Handler();
  }

}

void MX_SPI2_Init(void)
{

  /* SPI2 parameter configuration*/
  hspi2.Instance = SPI2;
  hspi2.Init.Mode = SPI_MODE_MASTER;
  hspi2.Init.Direction = SPI_DIRECTION_2LINES;
  hspi2.Init.DataSize = SPI_DATASIZE_8BIT;
  hspi2.Init.CLKPolarity = SPI_POLARITY_HIGH;
  hspi2.Init.CLKPhase = SPI_PHASE_2EDGE;
  hspi2.Init.NSS = SPI_NSS_SOFT;
  hspi2.Init.BaudRatePrescaler = SPI_BAUDRATEPRESCALER_8;
  hspi2.Init.FirstBit = SPI_FIRSTBIT_MSB;
  hspi2.Init.TIMode = SPI_TIMODE_DISABLE;
  hspi2.Init.CRCCalculation = SPI_CRCCALCULATION_DISABLE;
  hspi2.Init.CRCPolynomial = 0x0;
  hspi2.Init.NSSPMode = SPI_NSS_PULSE_ENABLE;
  hspi2.Init.NSSPolarity = SPI_NSS_POLARITY_LOW;
  hspi2.Init.FifoThreshold = SPI_FIFO_THRESHOLD_01DATA;
  hspi2.Init.TxCRCInitializationPattern = SPI_CRC_INITIALIZATION_ALL_ZERO_PATTERN;
  hspi2.Init.RxCRCInitializationPattern = SPI_CRC_INITIALIZATION_ALL_ZERO_PATTERN;
  hspi2.Init.MasterSSIdleness = SPI_MASTER_SS_IDLENESS_00CYCLE;
  hspi2.Init.MasterInterDataIdleness = SPI_MASTER_INTERDATA_IDLENESS_00CYCLE;
  hspi2.Init.MasterReceiverAutoSusp = SPI_MASTER_RX_AUTOSUSP_DISABLE;
  hspi2.Init.MasterKeepIOState = SPI_MASTER_KEEP_IO_STATE_ENABLE;
  hspi2.Init.IOSwap = SPI_IO_SWAP_DISABLE;
  if (HAL_SPI_Init(&hspi2) != HAL_OK)
  {
    Error_Handler();
  }

}

void MX_SPI5_Init(void)
{

  /* SPI5 parameter configuration*/
  hspi5.Instance = SPI5;
  hspi5.Init.Mode = SPI_MODE_MASTER;
  hspi5.Init.Direction = SPI_DIRECTION_2LINES;
  hspi5.Init.DataSize = SPI_DATASIZE_8BIT;
  hspi5.Init.CLKPolarity = SPI_POLARITY_HIGH;
  hspi5.Init.CLKPhase = SPI_PHASE_2EDGE;
  hspi5.Init.NSS = SPI_NSS_SOFT;
  hspi5.Init.BaudRatePrescaler = SPI_BAUDRATEPRESCALER_4;
  hspi5.Init.FirstBit = SPI_FIRSTBIT_MSB;
  hspi5.Init.TIMode = SPI_TIMODE_DISABLE;
  hspi5.Init.CRCCalculation = SPI_CRCCALCULATION_DISABLE;
  hspi5.Init.CRCPolynomial = 0x0;
  hspi5.Init.NSSPMode = SPI_NSS_PULSE_ENABLE;
  hspi5.Init.NSSPolarity = SPI_NSS_POLARITY_LOW;
  hspi5.Init.FifoThreshold = SPI_FIFO_THRESHOLD_01DATA;
  hspi5.Init.TxCRCInitializationPattern = SPI_CRC_INITIALIZATION_ALL_ZERO_PATTERN;
  hspi5.Init.RxCRCInitializationPattern = SPI_CRC_INITIALIZATION_ALL_ZERO_PATTERN;
  hspi5.Init.MasterSSIdleness = SPI_MASTER_SS_IDLENESS_00CYCLE;
  hspi5.Init.MasterInterDataIdleness = SPI_MASTER_INTERDATA_IDLENESS_00CYCLE;
  hspi5.Init.MasterReceiverAutoSusp = SPI_MASTER_RX_AUTOSUSP_DISABLE;
  hspi5.Init.MasterKeepIOState = SPI_MASTER_KEEP_IO_STATE_ENABLE;
  hspi5.Init.IOSwap = SPI_IO_SWAP_DISABLE;
  if (HAL_SPI_Init(&hspi5) != HAL_OK)
  {
    Error_Handler();
  }

}

void MX_SPI6_Init(void)
{

  /* SPI6 parameter configuration*/
  hspi6.Instance = SPI6;
  hspi6.Init.Mode = SPI_MODE_MASTER;
  hspi6.Init.Direction = SPI_DIRECTION_2LINES;
  hspi6.Init.DataSize = SPI_DATASIZE_8BIT;
  hspi6.Init.CLKPolarity = SPI_POLARITY_HIGH;
  hspi6.Init.CLKPhase = SPI_PHASE_2EDGE;
  hspi6.Init.NSS = SPI_NSS_SOFT;
  hspi6.Init.BaudRatePrescaler = SPI_BAUDRATEPRESCALER_8;
  hspi6.Init.FirstBit = SPI_FIRSTBIT_MSB;
  hspi6.Init.TIMode = SPI_TIMODE_DISABLE;
  hspi6.Init.CRCCalculation = SPI_CRCCALCULATION_DISABLE;
  hspi6.Init.CRCPolynomial = 0x0;
  hspi6.Init.NSSPMode = SPI_NSS_PULSE_ENABLE;
  hspi6.Init.NSSPolarity = SPI_NSS_POLARITY_LOW;
  hspi6.Init.FifoThreshold = SPI_FIFO_THRESHOLD_01DATA;
  hspi6.Init.TxCRCInitializationPattern = SPI_CRC_INITIALIZATION_ALL_ZERO_PATTERN;
  hspi6.Init.RxCRCInitializationPattern = SPI_CRC_INITIALIZATION_ALL_ZERO_PATTERN;
  hspi6.Init.MasterSSIdleness = SPI_MASTER_SS_IDLENESS_00CYCLE;
  hspi6.Init.MasterInterDataIdleness = SPI_MASTER_INTERDATA_IDLENESS_00CYCLE;
  hspi6.Init.MasterReceiverAutoSusp = SPI_MASTER_RX_AUTOSUSP_DISABLE;
  hspi6.Init.MasterKeepIOState = SPI_MASTER_KEEP_IO_STATE_ENABLE;
  hspi6.Init.IOSwap = SPI_IO_SWAP_DISABLE;
  if (HAL_SPI_Init(&hspi6) != HAL_OK)
  {
    Error_Handler();
  }

}

void MX_TIM1_Init(void)
{

  TIM_MasterConfigTypeDef sMasterConfig = {0};
  TIM_OC_InitTypeDef sConfigOC = {0};
  TIM_BreakDeadTimeConfigTypeDef sBreakDeadTimeConfig = {0};

  htim1.Instance = TIM1;
  htim1.Init.Prescaler = (199);
  htim1.Init.CounterMode = TIM_COUNTERMODE_UP;
  htim1.Init.Period = (20000);
  htim1.Init.ClockDivision = TIM_CLOCKDIVISION_DIV1;
  htim1.Init.RepetitionCounter = 0;
  htim1.Init.AutoReloadPreload = TIM_AUTORELOAD_PRELOAD_ENABLE;
  if (HAL_TIM_PWM_Init(&htim1) != HAL_OK)
  {
    Error_Handler();
  }
  sMasterConfig.MasterOutputTrigger = TIM_TRGO_RESET;
  sMasterConfig.MasterOutputTrigger2 = TIM_TRGO2_RESET;
  sMasterConfig.MasterSlaveMode = TIM_MASTERSLAVEMODE_DISABLE;
  if (HAL_TIMEx_MasterConfigSynchronization(&htim1, &sMasterConfig) != HAL_OK)
  {
    Error_Handler();
  }
  sConfigOC.OCMode = TIM_OCMODE_PWM1;
  sConfigOC.Pulse = (1500);
  sConfigOC.OCPolarity = TIM_OCPOLARITY_HIGH;
  sConfigOC.OCNPolarity = TIM_OCNPOLARITY_HIGH;
  sConfigOC.OCFastMode = TIM_OCFAST_DISABLE;
  sConfigOC.OCIdleState = TIM_OCIDLESTATE_RESET;
  sConfigOC.OCNIdleState = TIM_OCNIDLESTATE_RESET;
  if (HAL_TIM_PWM_ConfigChannel(&htim1, &sConfigOC, TIM_CHANNEL_1) != HAL_OK)
  {
    Error_Handler();
  }
  if (HAL_TIM_PWM_ConfigChannel(&htim1, &sConfigOC, TIM_CHANNEL_2) != HAL_OK)
  {
    Error_Handler();
  }
  if (HAL_TIM_PWM_ConfigChannel(&htim1, &sConfigOC, TIM_CHANNEL_3) != HAL_OK)
  {
    Error_Handler();
  }
  if (HAL_TIM_PWM_ConfigChannel(&htim1, &sConfigOC, TIM_CHANNEL_4) != HAL_OK)
  {
    Error_Handler();
  }
  sBreakDeadTimeConfig.OffStateRunMode = TIM_OSSR_DISABLE;
  sBreakDeadTimeConfig.OffStateIDLEMode = TIM_OSSI_DISABLE;
  sBreakDeadTimeConfig.LockLevel = TIM_LOCKLEVEL_OFF;
  sBreakDeadTimeConfig.DeadTime = 0;
  sBreakDeadTimeConfig.BreakState = TIM_BREAK_DISABLE;
  sBreakDeadTimeConfig.BreakPolarity = TIM_BREAKPOLARITY_HIGH;
  sBreakDeadTimeConfig.BreakFilter = 0;
  sBreakDeadTimeConfig.Break2State = TIM_BREAK2_DISABLE;
  sBreakDeadTimeConfig.Break2Polarity = TIM_BREAK2POLARITY_HIGH;
  sBreakDeadTimeConfig.Break2Filter = 0;
  sBreakDeadTimeConfig.AutomaticOutput = TIM_AUTOMATICOUTPUT_DISABLE;
  if (HAL_TIMEx_ConfigBreakDeadTime(&htim1, &sBreakDeadTimeConfig) != HAL_OK)
  {
    Error_Handler();
  }
  HAL_TIM_MspPostInit(&htim1);

}

void MX_TIM2_Init(void)
{

  TIM_MasterConfigTypeDef sMasterConfig = {0};
  TIM_OC_InitTypeDef sConfigOC = {0};

  htim2.Instance = TIM2;
  htim2.Init.Prescaler = 0;
  htim2.Init.CounterMode = TIM_COUNTERMODE_UP;
  htim2.Init.Period = 4294967295;
  htim2.Init.ClockDivision = TIM_CLOCKDIVISION_DIV1;
  htim2.Init.AutoReloadPreload = TIM_AUTORELOAD_PRELOAD_DISABLE;
  if (HAL_TIM_PWM_Init(&htim2) != HAL_OK)
  {
    Error_Handler();
  }
  sMasterConfig.MasterOutputTrigger = TIM_TRGO_RESET;
  sMasterConfig.MasterSlaveMode = TIM_MASTERSLAVEMODE_DISABLE;
  if (HAL_TIMEx_MasterConfigSynchronization(&htim2, &sMasterConfig) != HAL_OK)
  {
    Error_Handler();
  }
  sConfigOC.OCMode = TIM_OCMODE_PWM1;
  sConfigOC.Pulse = 0;
  sConfigOC.OCPolarity = TIM_OCPOLARITY_HIGH;
  sConfigOC.OCFastMode = TIM_OCFAST_DISABLE;
  if (HAL_TIM_PWM_ConfigChannel(&htim2, &sConfigOC, TIM_CHANNEL_1) != HAL_OK)
  {
    Error_Handler();
  }
  HAL_TIM_MspPostInit(&htim2);

}

void MX_TIM3_Init(void)
{

  TIM_MasterConfigTypeDef sMasterConfig = {0};
  TIM_IC_InitTypeDef sConfigIC = {0};

  htim3.Instance = TIM3;
  htim3.Init.Prescaler = 0;
  htim3.Init.CounterMode = TIM_COUNTERMODE_UP;
  htim3.Init.Period = 65535;
  htim3.Init.ClockDivision = TIM_CLOCKDIVISION_DIV1;
  htim3.Init.AutoReloadPreload = TIM_AUTORELOAD_PRELOAD_DISABLE;
  if (HAL_TIM_IC_Init(&htim3) != HAL_OK)
  {
    Error_Handler();
  }
  sMasterConfig.MasterOutputTrigger = TIM_TRGO_RESET;
  sMasterConfig.MasterSlaveMode = TIM_MASTERSLAVEMODE_DISABLE;
  if (HAL_TIMEx_MasterConfigSynchronization(&htim3, &sMasterConfig) != HAL_OK)
  {
    Error_Handler();
  }
  sConfigIC.ICPolarity = TIM_INPUTCHANNELPOLARITY_RISING;
  sConfigIC.ICSelection = TIM_ICSELECTION_DIRECTTI;
  sConfigIC.ICPrescaler = TIM_ICPSC_DIV1;
  sConfigIC.ICFilter = 0;
  if (HAL_TIM_IC_ConfigChannel(&htim3, &sConfigIC, TIM_CHANNEL_3) != HAL_OK)
  {
    Error_Handler();
  }

}

void MX_TIM4_Init(void)
{

  TIM_MasterConfigTypeDef sMasterConfig = {0};
  TIM_OC_InitTypeDef sConfigOC = {0};

  htim4.Instance = TIM4;
  htim4.Init.Prescaler = (199);
  htim4.Init.CounterMode = TIM_COUNTERMODE_UP;
  htim4.Init.Period = (20000);
  htim4.Init.ClockDivision = TIM_CLOCKDIVISION_DIV1;
  htim4.Init.AutoReloadPreload = TIM_AUTORELOAD_PRELOAD_ENABLE;
  if (HAL_TIM_PWM_Init(&htim4) != HAL_OK)
  {
    Error_Handler();
  }
  sMasterConfig.MasterOutputTrigger = TIM_TRGO_RESET;
  sMasterConfig.MasterSlaveMode = TIM_MASTERSLAVEMODE_DISABLE;
  if (HAL_TIMEx_MasterConfigSynchronization(&htim4, &sMasterConfig) != HAL_OK)
  {
    Error_Handler();
  }
  sConfigOC.OCMode = TIM_OCMODE_PWM1;
  sConfigOC.Pulse = (1500);
  sConfigOC.OCPolarity = TIM_OCPOLARITY_HIGH;
  sConfigOC.OCFastMode = TIM_OCFAST_DISABLE;
  if (HAL_TIM_PWM_ConfigChannel(&htim4, &sConfigOC, TIM_CHANNEL_2) != HAL_OK)
  {
    Error_Handler();
  }
  if (HAL_TIM_PWM_ConfigChannel(&htim4, &sConfigOC, TIM_CHANNEL_3) != HAL_OK)
  {
    Error_Handler();
  }
  HAL_TIM_MspPostInit(&htim4);

}

void MX_TIM5_Init(void)
{

  TIM_ClockConfigTypeDef sClockSourceConfig = {0};
  TIM_MasterConfigTypeDef sMasterConfig = {0};

  htim5.Instance = TIM5;
  htim5.Init.Prescaler = 199;
  htim5.Init.CounterMode = TIM_COUNTERMODE_UP;
  htim5.Init.Period = 4294967295;
  htim5.Init.ClockDivision = TIM_CLOCKDIVISION_DIV1;
  htim5.Init.AutoReloadPreload = TIM_AUTORELOAD_PRELOAD_DISABLE;
  if (HAL_TIM_Base_Init(&htim5) != HAL_OK)
  {
    Error_Handler();
  }
  sClockSourceConfig.ClockSource = TIM_CLOCKSOURCE_INTERNAL;
  if (HAL_TIM_ConfigClockSource(&htim5, &sClockSourceConfig) != HAL_OK)
  {
    Error_Handler();
  }
  sMasterConfig.MasterOutputTrigger = TIM_TRGO_ENABLE;
  sMasterConfig.MasterSlaveMode = TIM_MASTERSLAVEMODE_DISABLE;
  if (HAL_TIMEx_MasterConfigSynchronization(&htim5, &sMasterConfig) != HAL_OK)
  {
    Error_Handler();
  }

}

void MX_TIM7_Init(void)
{

  TIM_MasterConfigTypeDef sMasterConfig = {0};

  htim7.Instance = TIM7;
  htim7.Init.Prescaler = 199;
  htim7.Init.CounterMode = TIM_COUNTERMODE_UP;
  htim7.Init.Period = (POLLING_PERIOD_US);
  htim7.Init.AutoReloadPreload = TIM_AUTORELOAD_PRELOAD_ENABLE;
  if (HAL_TIM_Base_Init(&htim7) != HAL_OK)
  {
    Error_Handler();
  }
  sMasterConfig.MasterOutputTrigger = TIM_TRGO_RESET;
  sMasterConfig.MasterSlaveMode = TIM_MASTERSLAVEMODE_DISABLE;
  if (HAL_TIMEx_MasterConfigSynchronization(&htim7, &sMasterConfig) != HAL_OK)
  {
    Error_Handler();
  }

}

void MX_TIM8_Init(void)
{

  TIM_MasterConfigTypeDef sMasterConfig = {0};
  TIM_OC_InitTypeDef sConfigOC = {0};
  TIM_BreakDeadTimeConfigTypeDef sBreakDeadTimeConfig = {0};

  htim8.Instance = TIM8;
  htim8.Init.Prescaler = (199);
  htim8.Init.CounterMode = TIM_COUNTERMODE_UP;
  htim8.Init.Period = (20000);
  htim8.Init.ClockDivision = TIM_CLOCKDIVISION_DIV1;
  htim8.Init.RepetitionCounter = 0;
  htim8.Init.AutoReloadPreload = TIM_AUTORELOAD_PRELOAD_ENABLE;
  if (HAL_TIM_PWM_Init(&htim8) != HAL_OK)
  {
    Error_Handler();
  }
  sMasterConfig.MasterOutputTrigger = TIM_TRGO_RESET;
  sMasterConfig.MasterOutputTrigger2 = TIM_TRGO2_RESET;
  sMasterConfig.MasterSlaveMode = TIM_MASTERSLAVEMODE_DISABLE;
  if (HAL_TIMEx_MasterConfigSynchronization(&htim8, &sMasterConfig) != HAL_OK)
  {
    Error_Handler();
  }
  sConfigOC.OCMode = TIM_OCMODE_PWM1;
  sConfigOC.Pulse = (1500);
  sConfigOC.OCPolarity = TIM_OCPOLARITY_HIGH;
  sConfigOC.OCNPolarity = TIM_OCNPOLARITY_HIGH;
  sConfigOC.OCFastMode = TIM_OCFAST_DISABLE;
  sConfigOC.OCIdleState = TIM_OCIDLESTATE_RESET;
  sConfigOC.OCNIdleState = TIM_OCNIDLESTATE_RESET;
  if (HAL_TIM_PWM_ConfigChannel(&htim8, &sConfigOC, TIM_CHANNEL_1) != HAL_OK)
  {
    Error_Handler();
  }
  if (HAL_TIM_PWM_ConfigChannel(&htim8, &sConfigOC, TIM_CHANNEL_2) != HAL_OK)
  {
    Error_Handler();
  }
  sBreakDeadTimeConfig.OffStateRunMode = TIM_OSSR_DISABLE;
  sBreakDeadTimeConfig.OffStateIDLEMode = TIM_OSSI_DISABLE;
  sBreakDeadTimeConfig.LockLevel = TIM_LOCKLEVEL_OFF;
  sBreakDeadTimeConfig.DeadTime = 0;
  sBreakDeadTimeConfig.BreakState = TIM_BREAK_DISABLE;
  sBreakDeadTimeConfig.BreakPolarity = TIM_BREAKPOLARITY_HIGH;
  sBreakDeadTimeConfig.BreakFilter = 0;
  sBreakDeadTimeConfig.Break2State = TIM_BREAK2_DISABLE;
  sBreakDeadTimeConfig.Break2Polarity = TIM_BREAK2POLARITY_HIGH;
  sBreakDeadTimeConfig.Break2Filter = 0;
  sBreakDeadTimeConfig.AutomaticOutput = TIM_AUTOMATICOUTPUT_DISABLE;
  if (HAL_TIMEx_ConfigBreakDeadTime(&htim8, &sBreakDeadTimeConfig) != HAL_OK)
  {
    Error_Handler();
  }
  HAL_TIM_MspPostInit(&htim8);

}

void MX_TIM12_Init(void)
{

  TIM_SlaveConfigTypeDef sSlaveConfig = {0};
  TIM_MasterConfigTypeDef sMasterConfig = {0};

  htim12.Instance = TIM12;
  htim12.Init.Prescaler = 0;
  htim12.Init.CounterMode = TIM_COUNTERMODE_UP;
  htim12.Init.Period = 65535;
  htim12.Init.ClockDivision = TIM_CLOCKDIVISION_DIV1;
  htim12.Init.AutoReloadPreload = TIM_AUTORELOAD_PRELOAD_DISABLE;
  if (HAL_TIM_Base_Init(&htim12) != HAL_OK)
  {
    Error_Handler();
  }
  sSlaveConfig.SlaveMode = TIM_SLAVEMODE_EXTERNAL1;
  sSlaveConfig.InputTrigger = TIM_TS_ITR1;
  if (HAL_TIM_SlaveConfigSynchro(&htim12, &sSlaveConfig) != HAL_OK)
  {
    Error_Handler();
  }
  sMasterConfig.MasterOutputTrigger = TIM_TRGO_RESET;
  sMasterConfig.MasterSlaveMode = TIM_MASTERSLAVEMODE_ENABLE;
  if (HAL_TIMEx_MasterConfigSynchronization(&htim12, &sMasterConfig) != HAL_OK)
  {
    Error_Handler();
  }

}

void MX_UART4_Init(void)
{

  huart4.Instance = UART4;
  huart4.Init.BaudRate = 230400;
  huart4.Init.WordLength = UART_WORDLENGTH_8B;
  huart4.Init.StopBits = UART_STOPBITS_1;
  huart4.Init.Parity = UART_PARITY_NONE;
  huart4.Init.Mode = UART_MODE_TX_RX;
  huart4.Init.HwFlowCtl = UART_HWCONTROL_NONE;
  huart4.Init.OverSampling = UART_OVERSAMPLING_16;
  huart4.Init.OneBitSampling = UART_ONE_BIT_SAMPLE_DISABLE;
  huart4.Init.ClockPrescaler = UART_PRESCALER_DIV1;
  huart4.AdvancedInit.AdvFeatureInit = UART_ADVFEATURE_RXOVERRUNDISABLE_INIT;
  huart4.AdvancedInit.OverrunDisable = UART_ADVFEATURE_OVERRUN_DISABLE;
  if (HAL_UART_Init(&huart4) != HAL_OK)
  {
    Error_Handler();
  }
  if (HAL_UARTEx_SetTxFifoThreshold(&huart4, UART_TXFIFO_THRESHOLD_8_8) != HAL_OK)
  {
    Error_Handler();
  }
  if (HAL_UARTEx_SetRxFifoThreshold(&huart4, UART_RXFIFO_THRESHOLD_8_8) != HAL_OK)
  {
    Error_Handler();
  }
  if (HAL_UARTEx_EnableFifoMode(&huart4) != HAL_OK)
  {
    Error_Handler();
  }

}

void MX_UART7_Init(void)
{

  huart7.Instance = UART7;
  huart7.Init.BaudRate = 115200;
  huart7.Init.WordLength = UART_WORDLENGTH_8B;
  huart7.Init.StopBits = UART_STOPBITS_1;
  huart7.Init.Parity = UART_PARITY_NONE;
  huart7.Init.Mode = UART_MODE_TX_RX;
  huart7.Init.HwFlowCtl = UART_HWCONTROL_NONE;
  huart7.Init.OverSampling = UART_OVERSAMPLING_16;
  huart7.Init.OneBitSampling = UART_ONE_BIT_SAMPLE_DISABLE;
  huart7.Init.ClockPrescaler = UART_PRESCALER_DIV1;
  huart7.AdvancedInit.AdvFeatureInit = UART_ADVFEATURE_NO_INIT;
  if (HAL_UART_Init(&huart7) != HAL_OK)
  {
    Error_Handler();
  }
  if (HAL_UARTEx_SetTxFifoThreshold(&huart7, UART_TXFIFO_THRESHOLD_1_8) != HAL_OK)
  {
    Error_Handler();
  }
  if (HAL_UARTEx_SetRxFifoThreshold(&huart7, UART_RXFIFO_THRESHOLD_1_8) != HAL_OK)
  {
    Error_Handler();
  }
  if (HAL_UARTEx_DisableFifoMode(&huart7) != HAL_OK)
  {
    Error_Handler();
  }

}

void MX_UART8_Init(void)
{

  huart8.Instance = UART8;
  huart8.Init.BaudRate = 115200;
  huart8.Init.WordLength = UART_WORDLENGTH_8B;
  huart8.Init.StopBits = UART_STOPBITS_1;
  huart8.Init.Parity = UART_PARITY_NONE;
  huart8.Init.Mode = UART_MODE_TX_RX;
  huart8.Init.HwFlowCtl = UART_HWCONTROL_NONE;
  huart8.Init.OverSampling = UART_OVERSAMPLING_16;
  huart8.Init.OneBitSampling = UART_ONE_BIT_SAMPLE_DISABLE;
  huart8.Init.ClockPrescaler = UART_PRESCALER_DIV1;
  huart8.AdvancedInit.AdvFeatureInit = UART_ADVFEATURE_NO_INIT;
  if (HAL_UART_Init(&huart8) != HAL_OK)
  {
    Error_Handler();
  }
  if (HAL_UARTEx_SetTxFifoThreshold(&huart8, UART_TXFIFO_THRESHOLD_1_8) != HAL_OK)
  {
    Error_Handler();
  }
  if (HAL_UARTEx_SetRxFifoThreshold(&huart8, UART_RXFIFO_THRESHOLD_1_8) != HAL_OK)
  {
    Error_Handler();
  }
  if (HAL_UARTEx_DisableFifoMode(&huart8) != HAL_OK)
  {
    Error_Handler();
  }

}

void MX_USART1_UART_Init(void)
{

  huart1.Instance = USART1;
  huart1.Init.BaudRate = 115200;
  huart1.Init.WordLength = UART_WORDLENGTH_8B;
  huart1.Init.StopBits = UART_STOPBITS_1;
  huart1.Init.Parity = UART_PARITY_NONE;
  huart1.Init.Mode = UART_MODE_TX_RX;
  huart1.Init.HwFlowCtl = UART_HWCONTROL_NONE;
  huart1.Init.OverSampling = UART_OVERSAMPLING_16;
  huart1.Init.OneBitSampling = UART_ONE_BIT_SAMPLE_DISABLE;
  huart1.Init.ClockPrescaler = UART_PRESCALER_DIV1;
  huart1.AdvancedInit.AdvFeatureInit = UART_ADVFEATURE_NO_INIT;
  if (HAL_UART_Init(&huart1) != HAL_OK)
  {
    Error_Handler();
  }
  if (HAL_UARTEx_SetTxFifoThreshold(&huart1, UART_TXFIFO_THRESHOLD_1_8) != HAL_OK)
  {
    Error_Handler();
  }
  if (HAL_UARTEx_SetRxFifoThreshold(&huart1, UART_RXFIFO_THRESHOLD_1_8) != HAL_OK)
  {
    Error_Handler();
  }
  if (HAL_UARTEx_DisableFifoMode(&huart1) != HAL_OK)
  {
    Error_Handler();
  }

}

void MX_USART2_UART_Init(void)
{

  /* USER CODE BEGIN USART2_Init 0 */
#define UART2_BAUD        				(TELEM_BAUD)
  /* USER CODE END USART2_Init 0 */

  huart2.Instance = USART2;
  huart2.Init.BaudRate = (UART2_BAUD);
  huart2.Init.WordLength = UART_WORDLENGTH_8B;
  huart2.Init.StopBits = UART_STOPBITS_1;
  huart2.Init.Parity = UART_PARITY_NONE;
  huart2.Init.Mode = UART_MODE_TX_RX;
  huart2.Init.HwFlowCtl = UART_HWCONTROL_NONE;
  huart2.Init.OverSampling = UART_OVERSAMPLING_16;
  huart2.Init.OneBitSampling = UART_ONE_BIT_SAMPLE_DISABLE;
  huart2.Init.ClockPrescaler = UART_PRESCALER_DIV1;
  huart2.AdvancedInit.AdvFeatureInit = UART_ADVFEATURE_NO_INIT;
  if (HAL_UART_Init(&huart2) != HAL_OK)
  {
    Error_Handler();
  }
  if (HAL_UARTEx_SetTxFifoThreshold(&huart2, UART_TXFIFO_THRESHOLD_1_8) != HAL_OK)
  {
    Error_Handler();
  }
  if (HAL_UARTEx_SetRxFifoThreshold(&huart2, UART_RXFIFO_THRESHOLD_1_8) != HAL_OK)
  {
    Error_Handler();
  }
  if (HAL_UARTEx_DisableFifoMode(&huart2) != HAL_OK)
  {
    Error_Handler();
  }

}

void MX_USART3_UART_Init(void)
{

  huart3.Instance = USART3;
  huart3.Init.BaudRate = 115200;
  huart3.Init.WordLength = UART_WORDLENGTH_8B;
  huart3.Init.StopBits = UART_STOPBITS_1;
  huart3.Init.Parity = UART_PARITY_NONE;
  huart3.Init.Mode = UART_MODE_TX_RX;
  huart3.Init.HwFlowCtl = UART_HWCONTROL_RTS_CTS;
  huart3.Init.OverSampling = UART_OVERSAMPLING_16;
  huart3.Init.OneBitSampling = UART_ONE_BIT_SAMPLE_DISABLE;
  huart3.Init.ClockPrescaler = UART_PRESCALER_DIV1;
  huart3.AdvancedInit.AdvFeatureInit = UART_ADVFEATURE_NO_INIT;
  if (HAL_UART_Init(&huart3) != HAL_OK)
  {
    Error_Handler();
  }
  if (HAL_UARTEx_SetTxFifoThreshold(&huart3, UART_TXFIFO_THRESHOLD_1_8) != HAL_OK)
  {
    Error_Handler();
  }
  if (HAL_UARTEx_SetRxFifoThreshold(&huart3, UART_RXFIFO_THRESHOLD_1_8) != HAL_OK)
  {
    Error_Handler();
  }
  if (HAL_UARTEx_DisableFifoMode(&huart3) != HAL_OK)
  {
    Error_Handler();
  }

}

void MX_USART6_UART_Init(void)
{

  huart6.Instance = USART6;
  huart6.Init.BaudRate = 100000;
  huart6.Init.WordLength = UART_WORDLENGTH_9B;
  huart6.Init.StopBits = UART_STOPBITS_2;
  huart6.Init.Parity = UART_PARITY_EVEN;
  huart6.Init.Mode = UART_MODE_TX_RX;
  huart6.Init.HwFlowCtl = UART_HWCONTROL_NONE;
  huart6.Init.OverSampling = UART_OVERSAMPLING_16;
  huart6.Init.OneBitSampling = UART_ONE_BIT_SAMPLE_DISABLE;
  huart6.Init.ClockPrescaler = UART_PRESCALER_DIV1;
  huart6.AdvancedInit.AdvFeatureInit = UART_ADVFEATURE_TXINVERT_INIT|UART_ADVFEATURE_RXINVERT_INIT;
  huart6.AdvancedInit.TxPinLevelInvert = UART_ADVFEATURE_TXINV_ENABLE;
  huart6.AdvancedInit.RxPinLevelInvert = UART_ADVFEATURE_RXINV_ENABLE;
  if (HAL_UART_Init(&huart6) != HAL_OK)
  {
    Error_Handler();
  }
  if (HAL_UARTEx_SetTxFifoThreshold(&huart6, UART_TXFIFO_THRESHOLD_1_8) != HAL_OK)
  {
    Error_Handler();
  }
  if (HAL_UARTEx_SetRxFifoThreshold(&huart6, UART_RXFIFO_THRESHOLD_1_8) != HAL_OK)
  {
    Error_Handler();
  }
  if (HAL_UARTEx_DisableFifoMode(&huart6) != HAL_OK)
  {
    Error_Handler();
  }

}

void MX_USB_OTG_FS_PCD_Init(void)
{

  hpcd_USB_OTG_FS.Instance = USB_OTG_FS;
  hpcd_USB_OTG_FS.Init.dev_endpoints = 9;
  hpcd_USB_OTG_FS.Init.speed = PCD_SPEED_FULL;
  hpcd_USB_OTG_FS.Init.dma_enable = DISABLE;
  hpcd_USB_OTG_FS.Init.phy_itface = PCD_PHY_EMBEDDED;
  hpcd_USB_OTG_FS.Init.Sof_enable = DISABLE;
  hpcd_USB_OTG_FS.Init.low_power_enable = DISABLE;
  hpcd_USB_OTG_FS.Init.lpm_enable = DISABLE;
  hpcd_USB_OTG_FS.Init.battery_charging_enable = DISABLE;
  hpcd_USB_OTG_FS.Init.vbus_sensing_enable = DISABLE;
  hpcd_USB_OTG_FS.Init.use_dedicated_ep1 = DISABLE;
  if (HAL_PCD_Init(&hpcd_USB_OTG_FS) != HAL_OK)
  {
    Error_Handler();
  }

}

void MX_BDMA_Init(void)
{

  /* DMA controller clock enable */
  __HAL_RCC_BDMA_CLK_ENABLE();

  /* DMA interrupt init */
  /* BDMA_Channel0_IRQn interrupt configuration */
  HAL_NVIC_SetPriority(BDMA_Channel0_IRQn, 5, 0);
  HAL_NVIC_EnableIRQ(BDMA_Channel0_IRQn);
  /* BDMA_Channel1_IRQn interrupt configuration */
  HAL_NVIC_SetPriority(BDMA_Channel1_IRQn, 5, 0);
  HAL_NVIC_EnableIRQ(BDMA_Channel1_IRQn);
  /* BDMA_Channel2_IRQn interrupt configuration */
  HAL_NVIC_SetPriority(BDMA_Channel2_IRQn, 5, 0);
  HAL_NVIC_EnableIRQ(BDMA_Channel2_IRQn);

}

void MX_DMA_Init(void)
{

  /* DMA controller clock enable */
  __HAL_RCC_DMA1_CLK_ENABLE();
  __HAL_RCC_DMA2_CLK_ENABLE();

  /* DMA interrupt init */
  /* DMA1_Stream0_IRQn interrupt configuration */
  HAL_NVIC_SetPriority(DMA1_Stream0_IRQn, 5, 0);
  HAL_NVIC_EnableIRQ(DMA1_Stream0_IRQn);
  /* DMA1_Stream1_IRQn interrupt configuration */
  HAL_NVIC_SetPriority(DMA1_Stream1_IRQn, 5, 0);
  HAL_NVIC_EnableIRQ(DMA1_Stream1_IRQn);
  /* DMA1_Stream2_IRQn interrupt configuration */
  HAL_NVIC_SetPriority(DMA1_Stream2_IRQn, 5, 0);
  HAL_NVIC_EnableIRQ(DMA1_Stream2_IRQn);
  /* DMA1_Stream3_IRQn interrupt configuration */
  HAL_NVIC_SetPriority(DMA1_Stream3_IRQn, 5, 0);
  HAL_NVIC_EnableIRQ(DMA1_Stream3_IRQn);
  /* DMA1_Stream4_IRQn interrupt configuration */
  HAL_NVIC_SetPriority(DMA1_Stream4_IRQn, 5, 0);
  HAL_NVIC_EnableIRQ(DMA1_Stream4_IRQn);
  /* DMA1_Stream5_IRQn interrupt configuration */
  HAL_NVIC_SetPriority(DMA1_Stream5_IRQn, 5, 0);
  HAL_NVIC_EnableIRQ(DMA1_Stream5_IRQn);
  /* DMA1_Stream6_IRQn interrupt configuration */
  HAL_NVIC_SetPriority(DMA1_Stream6_IRQn, 5, 0);
  HAL_NVIC_EnableIRQ(DMA1_Stream6_IRQn);
  /* DMA1_Stream7_IRQn interrupt configuration */
  HAL_NVIC_SetPriority(DMA1_Stream7_IRQn, 5, 0);
  HAL_NVIC_EnableIRQ(DMA1_Stream7_IRQn);
  /* DMA2_Stream0_IRQn interrupt configuration */
  HAL_NVIC_SetPriority(DMA2_Stream0_IRQn, 1, 0);
  HAL_NVIC_EnableIRQ(DMA2_Stream0_IRQn);
  /* DMA2_Stream1_IRQn interrupt configuration */
  HAL_NVIC_SetPriority(DMA2_Stream1_IRQn, 5, 0);
  HAL_NVIC_EnableIRQ(DMA2_Stream1_IRQn);
  /* DMA2_Stream2_IRQn interrupt configuration */
  HAL_NVIC_SetPriority(DMA2_Stream2_IRQn, 5, 0);
  HAL_NVIC_EnableIRQ(DMA2_Stream2_IRQn);
  /* DMA2_Stream3_IRQn interrupt configuration */
  HAL_NVIC_SetPriority(DMA2_Stream3_IRQn, 5, 0);
  HAL_NVIC_EnableIRQ(DMA2_Stream3_IRQn);
  /* DMA2_Stream4_IRQn interrupt configuration */
  HAL_NVIC_SetPriority(DMA2_Stream4_IRQn, 0, 0);
  HAL_NVIC_EnableIRQ(DMA2_Stream4_IRQn);
  /* DMA2_Stream5_IRQn interrupt configuration */
  HAL_NVIC_SetPriority(DMA2_Stream5_IRQn, 5, 0);
  HAL_NVIC_EnableIRQ(DMA2_Stream5_IRQn);
  /* DMA2_Stream6_IRQn interrupt configuration */
  HAL_NVIC_SetPriority(DMA2_Stream6_IRQn, 5, 0);
  HAL_NVIC_EnableIRQ(DMA2_Stream6_IRQn);

}

void MX_GPIO_Init(void)
{
  GPIO_InitTypeDef GPIO_InitStruct = {0};

  /* GPIO Ports Clock Enable */
  __HAL_RCC_GPIOE_CLK_ENABLE();
  __HAL_RCC_GPIOB_CLK_ENABLE();
  __HAL_RCC_GPIOG_CLK_ENABLE();
  __HAL_RCC_GPIOD_CLK_ENABLE();
  __HAL_RCC_GPIOC_CLK_ENABLE();
  __HAL_RCC_GPIOA_CLK_ENABLE();
  __HAL_RCC_GPIOI_CLK_ENABLE();
  __HAL_RCC_GPIOH_CLK_ENABLE();
  __HAL_RCC_GPIOF_CLK_ENABLE();

  /*Configure GPIO pin Output Level */
  HAL_GPIO_WritePin(GPIOE, VDD_3V3_SENSORS_EN_Pin|SPEKTRUM_POWER_EN_Pin|ICM_20948_CS_Pin, GPIO_PIN_SET);

  /*Configure GPIO pin Output Level */
  HAL_GPIO_WritePin(GPIOB, LED_BLUE_Pin|LED_GREEN_Pin|LED_RED_Pin, GPIO_PIN_RESET);

  /*Configure GPIO pin Output Level */
  HAL_GPIO_WritePin(GPIOD, DPS310_CSn_Pin|FRAM_CS_Pin, GPIO_PIN_SET);

  /*Configure GPIO pin Output Level */
  HAL_GPIO_WritePin(GPIOG, EXTERNAL_SPI6_CS_Pin|PWM_VOLT_SEL_Pin, GPIO_PIN_SET);

  /*Configure GPIO pin Output Level */
  HAL_GPIO_WritePin(VDD_1V8_SENSORS_EN_GPIO_Port, VDD_1V8_SENSORS_EN_Pin, GPIO_PIN_SET);

  /*Configure GPIO pin Output Level */
  HAL_GPIO_WritePin(GPIOF, BMI088_INT2_ACCEL_Pin|CAN1_EN_Pin|CAN2_EN_Pin, GPIO_PIN_RESET);

  /*Configure GPIO pin Output Level */
  HAL_GPIO_WritePin(GPIOF, BMI088_ACCEL_CS_Pin|BMI088_GYRO_CS_Pin, GPIO_PIN_SET);

  /*Configure GPIO pin Output Level */
  HAL_GPIO_WritePin(ICM_20602_CS_GPIO_Port, ICM_20602_CS_Pin, GPIO_PIN_SET);

  /*Configure GPIO pins : VDD_3V3_SENSORS_EN_Pin SPEKTRUM_POWER_EN_Pin ICM_20948_CS_Pin */
  GPIO_InitStruct.Pin = VDD_3V3_SENSORS_EN_Pin|SPEKTRUM_POWER_EN_Pin|ICM_20948_CS_Pin;
  GPIO_InitStruct.Mode = GPIO_MODE_OUTPUT_PP;
  GPIO_InitStruct.Pull = GPIO_PULLUP;
  GPIO_InitStruct.Speed = GPIO_SPEED_FREQ_LOW;
  HAL_GPIO_Init(GPIOE, &GPIO_InitStruct);

  /*Configure GPIO pin : VDD_BRICK_VALID_Pin */
  GPIO_InitStruct.Pin = VDD_BRICK_VALID_Pin;
  GPIO_InitStruct.Mode = GPIO_MODE_INPUT;
  GPIO_InitStruct.Pull = GPIO_NOPULL;
  HAL_GPIO_Init(VDD_BRICK_VALID_GPIO_Port, &GPIO_InitStruct);

  /*Configure GPIO pins : LED_BLUE_Pin LED_GREEN_Pin LED_RED_Pin */
  GPIO_InitStruct.Pin = LED_BLUE_Pin|LED_GREEN_Pin|LED_RED_Pin;
  GPIO_InitStruct.Mode = GPIO_MODE_OUTPUT_PP;
  GPIO_InitStruct.Pull = GPIO_NOPULL;
  GPIO_InitStruct.Speed = GPIO_SPEED_FREQ_LOW;
  HAL_GPIO_Init(GPIOB, &GPIO_InitStruct);

  /*Configure GPIO pins : DPS310_CSn_Pin FRAM_CS_Pin */
  GPIO_InitStruct.Pin = DPS310_CSn_Pin|FRAM_CS_Pin;
  GPIO_InitStruct.Mode = GPIO_MODE_OUTPUT_PP;
  GPIO_InitStruct.Pull = GPIO_PULLUP;
  GPIO_InitStruct.Speed = GPIO_SPEED_FREQ_LOW;
  HAL_GPIO_Init(GPIOD, &GPIO_InitStruct);

  /*Configure GPIO pin : EXTERNAL_SPI6_CS_Pin */
  GPIO_InitStruct.Pin = EXTERNAL_SPI6_CS_Pin;
  GPIO_InitStruct.Mode = GPIO_MODE_OUTPUT_PP;
  GPIO_InitStruct.Pull = GPIO_PULLUP;
  GPIO_InitStruct.Speed = GPIO_SPEED_FREQ_LOW;
  HAL_GPIO_Init(EXTERNAL_SPI6_CS_GPIO_Port, &GPIO_InitStruct);

  /*Configure GPIO pin : VDD_1V8_SENSORS_EN_Pin */
  GPIO_InitStruct.Pin = VDD_1V8_SENSORS_EN_Pin;
  GPIO_InitStruct.Mode = GPIO_MODE_OUTPUT_PP;
  GPIO_InitStruct.Pull = GPIO_NOPULL;
  GPIO_InitStruct.Speed = GPIO_SPEED_FREQ_LOW;
  HAL_GPIO_Init(VDD_1V8_SENSORS_EN_GPIO_Port, &GPIO_InitStruct);

  /*Configure GPIO pin : USB_VBUS_Pin */
  GPIO_InitStruct.Pin = USB_VBUS_Pin;
  GPIO_InitStruct.Mode = GPIO_MODE_INPUT;
  GPIO_InitStruct.Pull = GPIO_NOPULL;
  HAL_GPIO_Init(USB_VBUS_GPIO_Port, &GPIO_InitStruct);

  /*Configure GPIO pins : BMI088_INT2_ACCEL_Pin CAN1_EN_Pin CAN2_EN_Pin */
  GPIO_InitStruct.Pin = BMI088_INT2_ACCEL_Pin|CAN1_EN_Pin|CAN2_EN_Pin;
  GPIO_InitStruct.Mode = GPIO_MODE_OUTPUT_PP;
  GPIO_InitStruct.Pull = GPIO_NOPULL;
  GPIO_InitStruct.Speed = GPIO_SPEED_FREQ_LOW;
  HAL_GPIO_Init(GPIOF, &GPIO_InitStruct);

  /*Configure GPIO pins : BMI088_INT1_ACCEL_Pin BMI088_INT3_GYRO_Pin BMI088_INT4_GYRO_Pin */
  GPIO_InitStruct.Pin = BMI088_INT1_ACCEL_Pin|BMI088_INT3_GYRO_Pin|BMI088_INT4_GYRO_Pin;
  GPIO_InitStruct.Mode = GPIO_MODE_IT_RISING;
  GPIO_InitStruct.Pull = GPIO_NOPULL;
  HAL_GPIO_Init(GPIOF, &GPIO_InitStruct);

  /*Configure GPIO pin : PWM_VOLT_SEL_Pin */
  GPIO_InitStruct.Pin = PWM_VOLT_SEL_Pin;
  GPIO_InitStruct.Mode = GPIO_MODE_OUTPUT_PP;
  GPIO_InitStruct.Pull = GPIO_NOPULL;
  GPIO_InitStruct.Speed = GPIO_SPEED_FREQ_LOW;
  HAL_GPIO_Init(PWM_VOLT_SEL_GPIO_Port, &GPIO_InitStruct);

  /*Configure GPIO pins : BMI088_ACCEL_CS_Pin BMI088_GYRO_CS_Pin */
  GPIO_InitStruct.Pin = BMI088_ACCEL_CS_Pin|BMI088_GYRO_CS_Pin;
  GPIO_InitStruct.Mode = GPIO_MODE_OUTPUT_PP;
  GPIO_InitStruct.Pull = GPIO_PULLUP;
  GPIO_InitStruct.Speed = GPIO_SPEED_FREQ_LOW;
  HAL_GPIO_Init(GPIOF, &GPIO_InitStruct);

  /*Configure GPIO pin : ICM_20602_DRDY_Pin */
  GPIO_InitStruct.Pin = ICM_20602_DRDY_Pin;
  GPIO_InitStruct.Mode = GPIO_MODE_INPUT;
  GPIO_InitStruct.Pull = GPIO_NOPULL;
  HAL_GPIO_Init(ICM_20602_DRDY_GPIO_Port, &GPIO_InitStruct);

  /*Configure GPIO pin : VBUS_VALID_Pin */
  GPIO_InitStruct.Pin = VBUS_VALID_Pin;
  GPIO_InitStruct.Mode = GPIO_MODE_INPUT;
  GPIO_InitStruct.Pull = GPIO_NOPULL;
  HAL_GPIO_Init(VBUS_VALID_GPIO_Port, &GPIO_InitStruct);

  /*Configure GPIO pin : ICM_20602_CS_Pin */
  GPIO_InitStruct.Pin = ICM_20602_CS_Pin;
  GPIO_InitStruct.Mode = GPIO_MODE_OUTPUT_PP;
  GPIO_InitStruct.Pull = GPIO_PULLUP;
  GPIO_InitStruct.Speed = GPIO_SPEED_FREQ_LOW;
  HAL_GPIO_Init(ICM_20602_CS_GPIO_Port, &GPIO_InitStruct);

  /*Configure GPIO pin : ICM_20948_DRDY_Pin */
  GPIO_InitStruct.Pin = ICM_20948_DRDY_Pin;
  GPIO_InitStruct.Mode = GPIO_MODE_IT_RISING;
  GPIO_InitStruct.Pull = GPIO_NOPULL;
  HAL_GPIO_Init(ICM_20948_DRDY_GPIO_Port, &GPIO_InitStruct);

  /* EXTI interrupt init*/
  HAL_NVIC_SetPriority(EXTI1_IRQn, 5, 0);
  HAL_NVIC_EnableIRQ(EXTI1_IRQn);

  HAL_NVIC_SetPriority(EXTI3_IRQn, 5, 0);
  HAL_NVIC_EnableIRQ(EXTI3_IRQn);

  HAL_NVIC_SetPriority(EXTI4_IRQn, 0, 0);
  HAL_NVIC_EnableIRQ(EXTI4_IRQn);

  HAL_NVIC_SetPriority(EXTI15_10_IRQn, 5, 0);
  HAL_NVIC_EnableIRQ(EXTI15_10_IRQn);

}

/* MPU Configuration */

void MPU_Config(void)
{
  MPU_Region_InitTypeDef MPU_InitStruct = {0};

  /* Disables the MPU */
  HAL_MPU_Disable();

  /** Initializes and configures the Region and the memory to be protected
  */
  MPU_InitStruct.Enable = MPU_REGION_ENABLE;
  MPU_InitStruct.Number = MPU_REGION_NUMBER0;
  MPU_InitStruct.BaseAddress = 0x30040000;
  MPU_InitStruct.Size = MPU_REGION_SIZE_32KB;
  MPU_InitStruct.SubRegionDisable = 0x0;
  MPU_InitStruct.TypeExtField = MPU_TEX_LEVEL0;
  MPU_InitStruct.AccessPermission = MPU_REGION_FULL_ACCESS;
  MPU_InitStruct.DisableExec = MPU_INSTRUCTION_ACCESS_ENABLE;
  MPU_InitStruct.IsShareable = MPU_ACCESS_SHAREABLE;
  MPU_InitStruct.IsCacheable = MPU_ACCESS_CACHEABLE;
  MPU_InitStruct.IsBufferable = MPU_ACCESS_NOT_BUFFERABLE;

  HAL_MPU_ConfigRegion(&MPU_InitStruct);

  /** Initializes and configures the Region and the memory to be protected
  */
  MPU_InitStruct.Number = MPU_REGION_NUMBER1;
  MPU_InitStruct.BaseAddress = 0x38000000;
  MPU_InitStruct.Size = MPU_REGION_SIZE_64KB;

  HAL_MPU_ConfigRegion(&MPU_InitStruct);
  /* Enables the MPU */
  HAL_MPU_Enable(MPU_PRIVILEGED_DEFAULT);

}

void Error_Handler(void)
{
  __disable_irq();
  while (1)
  {
  }
}
